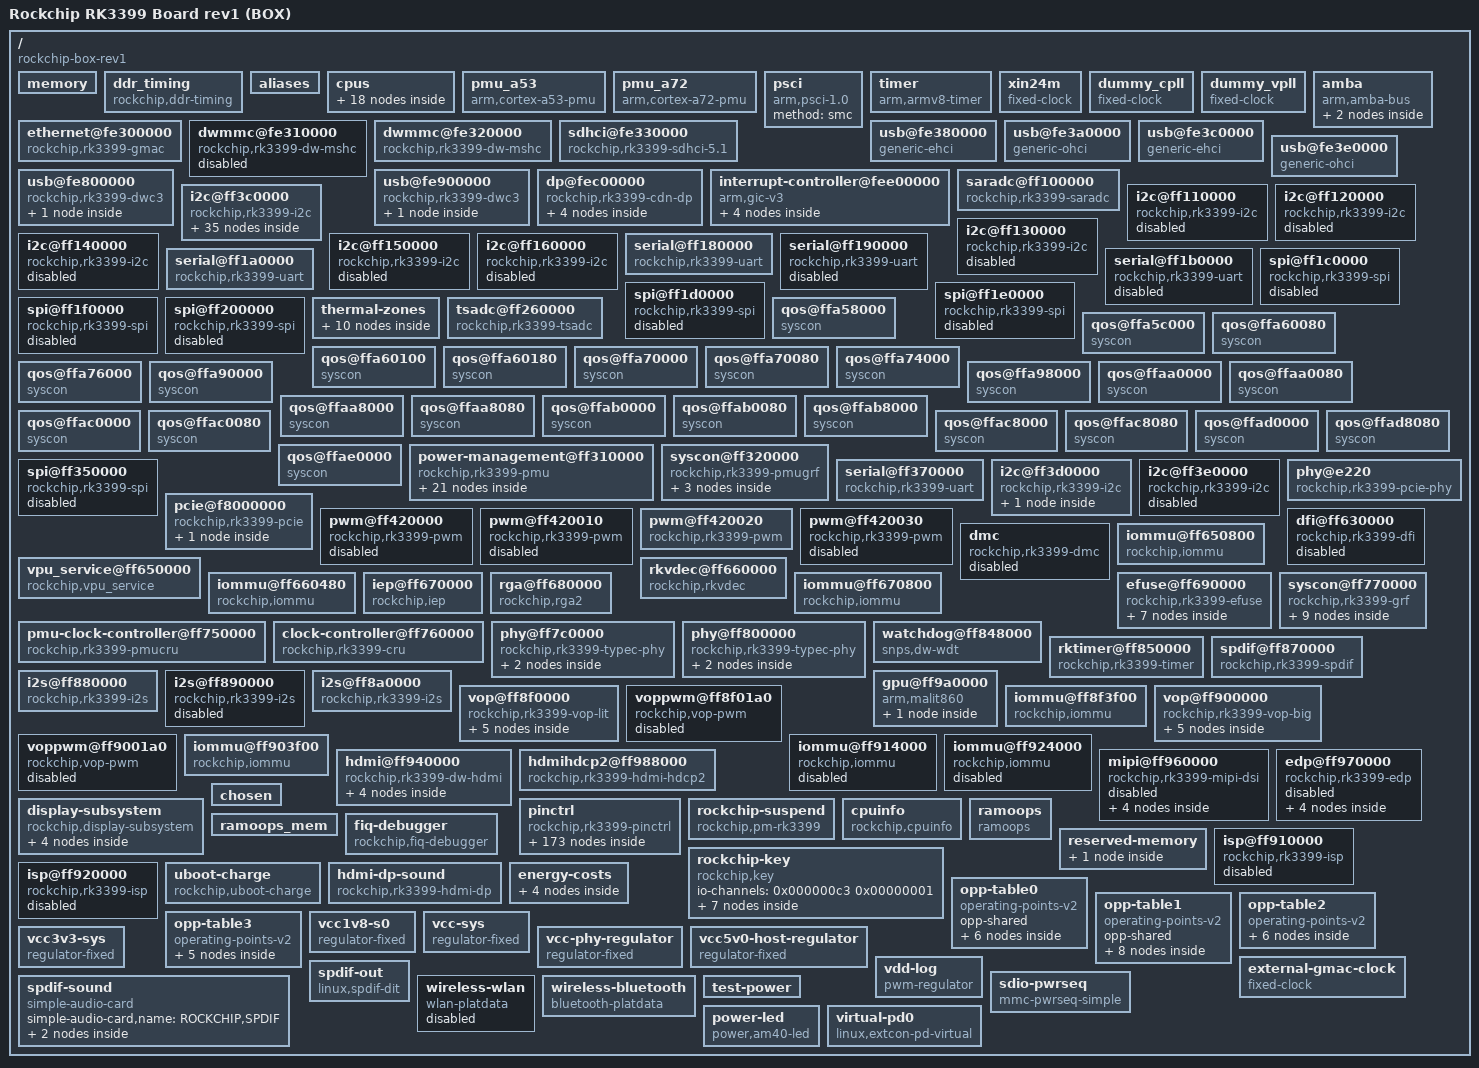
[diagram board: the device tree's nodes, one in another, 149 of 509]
/dts-v1/;
// magic:		0xd00dfeed
// totalsize:		0x12080 (73856)
// off_dt_struct:	0x58
// off_dt_strings:	0xfeb8
// off_mem_rsvmap:	0x28
// version:		17
// last_comp_version:	16
// boot_cpuid_phys:	0x0
// size_dt_strings:	0x136e
// size_dt_struct:	0xfe60

/memreserve/ 0x5600000 0x12000;
/memreserve/ 0x5bf0000 0x1adaf8;
/ {
    compatible = "rockchip-box-rev1", "rockchip,rk3399-box";
    interrupt-parent = <0x00000001>;
    #address-cells = <0x00000002>;
    #size-cells = <0x00000002>;
    model = "Rockchip RK3399 Board rev1 (BOX)";
    memory {
        reg = <0x00000000 0x00200000 0x00000000 0x08200000 0x00000000 0x09400000 0x00000000 0xeec00000>;
        device_type = "memory";
    };
    ddr_timing {
        compatible = "rockchip,ddr-timing";
        ddr3_speed_bin = <0x00000015>;
        pd_idle = <0x00000000>;
        sr_idle = <0x00000000>;
        sr_mc_gate_idle = <0x00000000>;
        srpd_lite_idle = <0x00000000>;
        standby_idle = <0x00000000>;
        dram_dll_dis_freq = <0x0000012c>;
        phy_dll_dis_freq = <0x0000007d>;
        ddr3_odt_dis_freq = <0x0000014d>;
        ddr3_drv = <0x00000028>;
        ddr3_odt = <0x00000078>;
        phy_ddr3_ca_drv = <0x00000028>;
        phy_ddr3_dq_drv = <0x00000028>;
        phy_ddr3_odt = <0x000000f0>;
        lpddr3_odt_dis_freq = <0x0000014d>;
        lpddr3_drv = <0x00000022>;
        lpddr3_odt = <0x000000f0>;
        phy_lpddr3_ca_drv = <0x00000028>;
        phy_lpddr3_dq_drv = <0x00000028>;
        phy_lpddr3_odt = <0x000000f0>;
        lpddr4_odt_dis_freq = <0x0000014d>;
        lpddr4_drv = <0x0000003c>;
        lpddr4_dq_odt = <0x00000028>;
        lpddr4_ca_odt = <0x00000028>;
        phy_lpddr4_ca_drv = <0x00000028>;
        phy_lpddr4_ck_cs_drv = <0x00000050>;
        phy_lpddr4_dq_drv = <0x00000050>;
        phy_lpddr4_odt = <0x0000003c>;
        linux,phandle = <0x0000008b>;
        phandle = <0x0000008b>;
    };
    aliases {
        i2c0 = "/i2c@ff3c0000";
        i2c1 = "/i2c@ff110000";
        i2c2 = "/i2c@ff120000";
        i2c3 = "/i2c@ff130000";
        i2c4 = "/i2c@ff3d0000";
        i2c5 = "/i2c@ff140000";
        i2c6 = "/i2c@ff150000";
        i2c7 = "/i2c@ff160000";
        i2c8 = "/i2c@ff3e0000";
        serial0 = "/serial@ff180000";
        serial1 = "/serial@ff190000";
        serial2 = "/serial@ff1a0000";
        serial3 = "/serial@ff1b0000";
        serial4 = "/serial@ff370000";
    };
    cpus {
        #address-cells = <0x00000002>;
        #size-cells = <0x00000000>;
        cpu-map {
            cluster0 {
                core0 {
                    cpu = <0x00000002>;
                };
                core1 {
                    cpu = <0x00000003>;
                };
                core2 {
                    cpu = <0x00000004>;
                };
                core3 {
                    cpu = <0x00000005>;
                };
            };
            cluster1 {
                core0 {
                    cpu = <0x00000006>;
                };
                core1 {
                    cpu = <0x00000007>;
                };
            };
        };
        cpu@0 {
            device_type = "cpu";
            compatible = "arm,cortex-a53", "arm,armv8";
            reg = <0x00000000 0x00000000>;
            enable-method = "psci";
            #cooling-cells = <0x00000002>;
            dynamic-power-coefficient = <0x00000064>;
            clocks = <0x00000008 0x00000008>;
            cpu-idle-states = <0x00000009 0x0000000a>;
            operating-points-v2 = <0x0000000b>;
            sched-energy-costs = <0x0000000c 0x0000000d>;
            cpu-supply = <0x0000000e>;
            linux,phandle = <0x00000002>;
            phandle = <0x00000002>;
        };
        cpu@1 {
            device_type = "cpu";
            compatible = "arm,cortex-a53", "arm,armv8";
            reg = <0x00000000 0x00000001>;
            enable-method = "psci";
            clocks = <0x00000008 0x00000008>;
            cpu-idle-states = <0x00000009 0x0000000a>;
            operating-points-v2 = <0x0000000b>;
            sched-energy-costs = <0x0000000c 0x0000000d>;
            cpu-supply = <0x0000000e>;
            linux,phandle = <0x00000003>;
            phandle = <0x00000003>;
        };
        cpu@2 {
            device_type = "cpu";
            compatible = "arm,cortex-a53", "arm,armv8";
            reg = <0x00000000 0x00000002>;
            enable-method = "psci";
            clocks = <0x00000008 0x00000008>;
            cpu-idle-states = <0x00000009 0x0000000a>;
            operating-points-v2 = <0x0000000b>;
            sched-energy-costs = <0x0000000c 0x0000000d>;
            cpu-supply = <0x0000000e>;
            linux,phandle = <0x00000004>;
            phandle = <0x00000004>;
        };
        cpu@3 {
            device_type = "cpu";
            compatible = "arm,cortex-a53", "arm,armv8";
            reg = <0x00000000 0x00000003>;
            enable-method = "psci";
            clocks = <0x00000008 0x00000008>;
            cpu-idle-states = <0x00000009 0x0000000a>;
            operating-points-v2 = <0x0000000b>;
            sched-energy-costs = <0x0000000c 0x0000000d>;
            cpu-supply = <0x0000000e>;
            linux,phandle = <0x00000005>;
            phandle = <0x00000005>;
        };
        cpu@100 {
            device_type = "cpu";
            compatible = "arm,cortex-a72", "arm,armv8";
            reg = <0x00000000 0x00000100>;
            enable-method = "psci";
            #cooling-cells = <0x00000002>;
            dynamic-power-coefficient = <0x000001b4>;
            clocks = <0x00000008 0x00000009>;
            cpu-idle-states = <0x00000009 0x0000000a>;
            operating-points-v2 = <0x0000000f>;
            sched-energy-costs = <0x00000010 0x00000011>;
            cpu-supply = <0x00000012>;
            linux,phandle = <0x00000006>;
            phandle = <0x00000006>;
        };
        cpu@101 {
            device_type = "cpu";
            compatible = "arm,cortex-a72", "arm,armv8";
            reg = <0x00000000 0x00000101>;
            enable-method = "psci";
            clocks = <0x00000008 0x00000009>;
            cpu-idle-states = <0x00000009 0x0000000a>;
            operating-points-v2 = <0x0000000f>;
            sched-energy-costs = <0x00000010 0x00000011>;
            cpu-supply = <0x00000012>;
            linux,phandle = <0x00000007>;
            phandle = <0x00000007>;
        };
        idle-states {
            entry-method = "psci";
            cpu-sleep {
                compatible = "arm,idle-state";
                local-timer-stop;
                arm,psci-suspend-param = <0x00010000>;
                entry-latency-us = <0x00000078>;
                exit-latency-us = <0x000000fa>;
                min-residency-us = <0x00000384>;
                linux,phandle = <0x00000009>;
                phandle = <0x00000009>;
            };
            cluster-sleep {
                compatible = "arm,idle-state";
                local-timer-stop;
                arm,psci-suspend-param = <0x01010000>;
                entry-latency-us = <0x00000190>;
                exit-latency-us = <0x000001f4>;
                min-residency-us = <0x000007d0>;
                linux,phandle = <0x0000000a>;
                phandle = <0x0000000a>;
            };
        };
    };
    pmu_a53 {
        compatible = "arm,cortex-a53-pmu";
        interrupts = <0x00000001 0x00000007 0x00000008 0x00000013>;
    };
    pmu_a72 {
        compatible = "arm,cortex-a72-pmu";
        interrupts = <0x00000001 0x00000007 0x00000008 0x00000014>;
    };
    psci {
        compatible = "arm,psci-1.0";
        method = "smc";
    };
    timer {
        compatible = "arm,armv8-timer";
        interrupts = <0x00000001 0x0000000d 0x00000008 0x00000000 0x00000001 0x0000000e 0x00000008 0x00000000 0x00000001 0x0000000b 0x00000008 0x00000000 0x00000001 0x0000000a 0x00000008 0x00000000>;
    };
    xin24m {
        compatible = "fixed-clock";
        clock-frequency = <0x016e3600>;
        clock-output-names = "xin24m";
        #clock-cells = <0x00000000>;
    };
    dummy_cpll {
        compatible = "fixed-clock";
        clock-frequency = <0x00000000>;
        clock-output-names = "dummy_cpll";
        #clock-cells = <0x00000000>;
    };
    dummy_vpll {
        compatible = "fixed-clock";
        clock-frequency = <0x00000000>;
        clock-output-names = "dummy_vpll";
        #clock-cells = <0x00000000>;
    };
    amba {
        compatible = "arm,amba-bus";
        #address-cells = <0x00000002>;
        #size-cells = <0x00000002>;
        ranges;
        dma-controller@ff6d0000 {
            compatible = "arm,pl330", "arm,primecell";
            reg = <0x00000000 0xff6d0000 0x00000000 0x00004000>;
            interrupts = <0x00000000 0x00000005 0x00000004 0x00000000 0x00000000 0x00000006 0x00000004 0x00000000>;
            #dma-cells = <0x00000001>;
            clocks = <0x00000008 0x000000d3>;
            clock-names = "apb_pclk";
            peripherals-req-type-burst;
            linux,phandle = <0x00000094>;
            phandle = <0x00000094>;
        };
        dma-controller@ff6e0000 {
            compatible = "arm,pl330", "arm,primecell";
            reg = <0x00000000 0xff6e0000 0x00000000 0x00004000>;
            interrupts = <0x00000000 0x00000007 0x00000004 0x00000000 0x00000000 0x00000008 0x00000004 0x00000000>;
            #dma-cells = <0x00000001>;
            clocks = <0x00000008 0x000000d4>;
            clock-names = "apb_pclk";
            peripherals-req-type-burst;
        };
    };
    ethernet@fe300000 {
        compatible = "rockchip,rk3399-gmac";
        reg = <0x00000000 0xfe300000 0x00000000 0x00010000>;
        rockchip,grf = <0x00000015>;
        interrupts = <0x00000000 0x0000000c 0x00000004 0x00000000>;
        interrupt-names = "macirq";
        clocks = <0x00000008 0x00000069 0x00000008 0x00000067 0x00000008 0x00000068 0x00000008 0x00000066 0x00000008 0x0000006a 0x00000008 0x000000d5 0x00000008 0x00000166>;
        clock-names = "stmmaceth", "mac_clk_rx", "mac_clk_tx", "clk_mac_ref", "clk_mac_refout", "aclk_mac", "pclk_mac";
        resets = <0x00000008 0x00000089>;
        reset-names = "stmmaceth";
        status = "okay";
        phy-supply = <0x00000016>;
        phy-mode = "rgmii";
        clock_in_out = "input";
        snps,reset-gpio = <0x00000017 0x0000000f 0x00000001>;
        snps,reset-active-low;
        snps,reset-delays-us = <0x00000000 0x000186a0 0x000186a0>;
        assigned-clocks = <0x00000008 0x000000a6>;
        assigned-clock-parents = <0x00000018>;
        pinctrl-names = "default";
        pinctrl-0 = <0x00000019>;
        wolirq-gpio = <0x0000001a 0x00000014 0x00000001>;
        tx_delay = <0x00000028>;
        rx_delay = <0x00000011>;
        lan_name = "RTL8211F";
        wakeup_ms = <0x00003a98>;
    };
    dwmmc@fe310000 {
        compatible = "rockchip,rk3399-dw-mshc", "rockchip,rk3288-dw-mshc";
        reg = <0x00000000 0xfe310000 0x00000000 0x00004000>;
        interrupts = <0x00000000 0x00000040 0x00000004 0x00000000>;
        clock-freq-min-max = <0x00030d40 0x05f5e100>;
        clocks = <0x00000008 0x000001ee 0x00000008 0x0000004d 0x00000008 0x0000009c 0x00000008 0x0000009d>;
        clock-names = "biu", "ciu", "ciu-drive", "ciu-sample";
        fifo-depth = <0x00000100>;
        power-domains = <0x0000001b 0x0000001c>;
        status = "disabled";
        clock-frequency = <0x05f5e100>;
        supports-sdio;
        bus-width = <0x00000004>;
        disable-wp;
        cap-sd-highspeed;
        cap-sdio-irq;
        keep-power-in-suspend;
        mmc-pwrseq = <0x0000001c>;
        non-removable;
        num-slots = <0x00000001>;
        pinctrl-names = "default";
        pinctrl-0 = <0x0000001d 0x0000001e 0x0000001f>;
        sd-uhs-sdr104;
    };
    dwmmc@fe320000 {
        compatible = "rockchip,rk3399-dw-mshc", "rockchip,rk3288-dw-mshc";
        reg = <0x00000000 0xfe320000 0x00000000 0x00004000>;
        interrupts = <0x00000000 0x00000041 0x00000004 0x00000000>;
        clock-freq-min-max = <0x000186a0 0x05f5e100>;
        clocks = <0x00000008 0x000001ce 0x00000008 0x0000004c 0x00000008 0x0000009a 0x00000008 0x0000009b>;
        clock-names = "biu", "ciu", "ciu-drive", "ciu-sample";
        fifo-depth = <0x00000100>;
        power-domains = <0x0000001b 0x0000001b>;
        status = "okay";
        clock-frequency = <0x05f5e100>;
        supports-sd;
        bus-width = <0x00000004>;
        cap-mmc-highspeed;
        cap-sd-highspeed;
        disable-wp;
        num-slots = <0x00000001>;
        vqmmc-supply = <0x00000020>;
        pinctrl-names = "default";
        pinctrl-0 = <0x00000021 0x00000022 0x00000023 0x00000024>;
        card-detect-delay = <0x00000320>;
    };
    sdhci@fe330000 {
        compatible = "rockchip,rk3399-sdhci-5.1", "arasan,sdhci-5.1";
        reg = <0x00000000 0xfe330000 0x00000000 0x00010000>;
        interrupts = <0x00000000 0x0000000b 0x00000004 0x00000000>;
        arasan,soc-ctl-syscon = <0x00000015>;
        assigned-clocks = <0x00000008 0x0000004e>;
        assigned-clock-rates = <0x0bebc200>;
        clocks = <0x00000008 0x0000004e 0x00000008 0x000000f0>;
        clock-names = "clk_xin", "clk_ahb";
        clock-output-names = "emmc_cardclock";
        #clock-cells = <0x00000000>;
        phys = <0x00000025>;
        phy-names = "phy_arasan";
        power-domains = <0x0000001b 0x00000017>;
        status = "okay";
        assigned-clock-parents = <0x00000008 0x00000005>;
        bus-width = <0x00000008>;
        mmc-hs400-1_8v;
        supports-emmc;
        non-removable;
        mmc-hs400-enhanced-strobe;
        linux,phandle = <0x00000092>;
        phandle = <0x00000092>;
    };
    usb@fe380000 {
        compatible = "generic-ehci";
        reg = <0x00000000 0xfe380000 0x00000000 0x00020000>;
        interrupts = <0x00000000 0x0000001a 0x00000004 0x00000000>;
        clocks = <0x00000008 0x000001c8 0x00000008 0x000001c9 0x00000008 0x000000a8>;
        clock-names = "hclk_host0", "hclk_host0_arb", "usbphy0_480m";
        phys = <0x00000026>;
        phy-names = "usb";
        power-domains = <0x0000001b 0x0000000e>;
        status = "okay";
    };
    usb@fe3a0000 {
        compatible = "generic-ohci";
        reg = <0x00000000 0xfe3a0000 0x00000000 0x00020000>;
        interrupts = <0x00000000 0x0000001c 0x00000004 0x00000000>;
        clocks = <0x00000008 0x000001c8 0x00000008 0x000001c9 0x00000008 0x000000a8>;
        clock-names = "hclk_host0", "hclk_host0_arb", "usbphy0_480m";
        phys = <0x00000026>;
        phy-names = "usb";
        power-domains = <0x0000001b 0x0000000e>;
        status = "okay";
    };
    usb@fe3c0000 {
        compatible = "generic-ehci";
        reg = <0x00000000 0xfe3c0000 0x00000000 0x00020000>;
        interrupts = <0x00000000 0x0000001e 0x00000004 0x00000000>;
        clocks = <0x00000008 0x000001ca 0x00000008 0x000001cb 0x00000008 0x000000a9>;
        clock-names = "hclk_host1", "hclk_host1_arb", "usbphy1_480m";
        phys = <0x00000027>;
        phy-names = "usb";
        power-domains = <0x0000001b 0x0000000e>;
        status = "okay";
    };
    usb@fe3e0000 {
        compatible = "generic-ohci";
        reg = <0x00000000 0xfe3e0000 0x00000000 0x00020000>;
        interrupts = <0x00000000 0x00000020 0x00000004 0x00000000>;
        clocks = <0x00000008 0x000001ca 0x00000008 0x000001cb 0x00000008 0x000000a9>;
        clock-names = "hclk_host1", "hclk_host1_arb", "usbphy1_480m";
        phys = <0x00000027>;
        phy-names = "usb";
        power-domains = <0x0000001b 0x0000000e>;
        status = "okay";
    };
    usb@fe800000 {
        compatible = "rockchip,rk3399-dwc3";
        clocks = <0x00000008 0x00000081 0x00000008 0x00000083 0x00000008 0x000000f6 0x00000008 0x000000f9>;
        clock-names = "ref_clk", "suspend_clk", "bus_clk", "grf_clk";
        power-domains = <0x0000001b 0x00000018>;
        resets = <0x00000008 0x00000125>;
        reset-names = "usb3-otg";
        #address-cells = <0x00000002>;
        #size-cells = <0x00000002>;
        ranges;
        status = "okay";
        extcon = <0x00000028>;
        dwc3@fe800000 {
            compatible = "snps,dwc3";
            reg = <0x00000000 0xfe800000 0x00000000 0x00100000>;
            interrupts = <0x00000000 0x00000069 0x00000004 0x00000000>;
            dr_mode = "otg";
            phys = <0x00000029 0x0000002a>;
            phy-names = "usb2-phy", "usb3-phy";
            phy_type = "utmi_wide";
            snps,dis_enblslpm_quirk;
            snps,dis-u2-freeclk-exists-quirk;
            snps,dis_u2_susphy_quirk;
            snps,dis-del-phy-power-chg-quirk;
            snps,tx-ipgap-linecheck-dis-quirk;
            snps,xhci-slow-suspend-quirk;
            snps,usb3-warm-reset-on-resume-quirk;
            status = "okay";
        };
    };
    usb@fe900000 {
        compatible = "rockchip,rk3399-dwc3";
        clocks = <0x00000008 0x00000082 0x00000008 0x00000084 0x00000008 0x000000f7 0x00000008 0x000000f9>;
        clock-names = "ref_clk", "suspend_clk", "bus_clk", "grf_clk";
        power-domains = <0x0000001b 0x00000018>;
        resets = <0x00000008 0x00000126>;
        reset-names = "usb3-otg";
        #address-cells = <0x00000002>;
        #size-cells = <0x00000002>;
        ranges;
        status = "okay";
        dwc3@fe900000 {
            compatible = "snps,dwc3";
            reg = <0x00000000 0xfe900000 0x00000000 0x00100000>;
            interrupts = <0x00000000 0x0000006e 0x00000004 0x00000000>;
            dr_mode = "host";
            phys = <0x0000002b 0x0000002c>;
            phy-names = "usb2-phy", "usb3-phy";
            phy_type = "utmi_wide";
            snps,dis_enblslpm_quirk;
            snps,dis-u2-freeclk-exists-quirk;
            snps,dis_u2_susphy_quirk;
            snps,dis-del-phy-power-chg-quirk;
            snps,tx-ipgap-linecheck-dis-quirk;
            snps,xhci-slow-suspend-quirk;
            snps,usb3-warm-reset-on-resume-quirk;
            status = "okay";
        };
    };
    dp@fec00000 {
        compatible = "rockchip,rk3399-cdn-dp";
        reg = <0x00000000 0xfec00000 0x00000000 0x00100000>;
        interrupts = <0x00000000 0x00000009 0x00000004>;
        clocks = <0x00000008 0x00000072 0x00000008 0x00000175 0x00000008 0x000000a1 0x00000008 0x0000016f>;
        clock-names = "core-clk", "pclk", "spdif", "grf";
        assigned-clocks = <0x00000008 0x00000072>;
        assigned-clock-rates = <0x05f5e100>;
        power-domains = <0x0000001b 0x00000015>;
        phys = <0x0000002d 0x0000002e>;
        resets = <0x00000008 0x00000103 0x00000008 0x00000148 0x00000008 0x0000014a 0x00000008 0x000000fd>;
        reset-names = "spdif", "dptx", "apb", "core";
        rockchip,grf = <0x00000015>;
        #address-cells = <0x00000001>;
        #size-cells = <0x00000000>;
        #sound-dai-cells = <0x00000001>;
        status = "okay";
        extcon = <0x0000002f>;
        dp_vop_sel = <0x00000001>;
        linux,phandle = <0x000000cd>;
        phandle = <0x000000cd>;
        ports {
            #address-cells = <0x00000001>;
            #size-cells = <0x00000000>;
            port {
                #address-cells = <0x00000001>;
                #size-cells = <0x00000000>;
                endpoint@0 {
                    reg = <0x00000000>;
                    remote-endpoint = <0x00000030>;
                    status = "disabled";
                    linux,phandle = <0x000000a4>;
                    phandle = <0x000000a4>;
                };
                endpoint@1 {
                    reg = <0x00000001>;
                    remote-endpoint = <0x00000031>;
                    linux,phandle = <0x0000009e>;
                    phandle = <0x0000009e>;
                };
            };
        };
    };
    interrupt-controller@fee00000 {
        compatible = "arm,gic-v3";
        #interrupt-cells = <0x00000004>;
        #address-cells = <0x00000002>;
        #size-cells = <0x00000002>;
        ranges;
        interrupt-controller;
        reg = <0x00000000 0xfee00000 0x00000000 0x00010000 0x00000000 0xfef00000 0x00000000 0x000c0000 0x00000000 0xfff00000 0x00000000 0x00010000 0x00000000 0xfff10000 0x00000000 0x00010000 0x00000000 0xfff20000 0x00000000 0x00010000>;
        interrupts = <0x00000001 0x00000009 0x00000004 0x00000000>;
        linux,phandle = <0x00000001>;
        phandle = <0x00000001>;
        interrupt-controller@fee20000 {
            compatible = "arm,gic-v3-its";
            msi-controller;
            reg = <0x00000000 0xfee20000 0x00000000 0x00020000>;
            linux,phandle = <0x00000081>;
            phandle = <0x00000081>;
        };
        ppi-partitions {
            interrupt-partition-0 {
                affinity = <0x00000002 0x00000003 0x00000004 0x00000005>;
                linux,phandle = <0x00000013>;
                phandle = <0x00000013>;
            };
            interrupt-partition-1 {
                affinity = <0x00000006 0x00000007>;
                linux,phandle = <0x00000014>;
                phandle = <0x00000014>;
            };
        };
    };
    saradc@ff100000 {
        compatible = "rockchip,rk3399-saradc";
        reg = <0x00000000 0xff100000 0x00000000 0x00000100>;
        interrupts = <0x00000000 0x0000003e 0x00000004 0x00000000>;
        #io-channel-cells = <0x00000001>;
        clocks = <0x00000008 0x00000050 0x00000008 0x00000165>;
        clock-names = "saradc", "apb_pclk";
        resets = <0x00000008 0x000000d4>;
        reset-names = "saradc-apb";
        status = "okay";
        linux,phandle = <0x000000c3>;
        phandle = <0x000000c3>;
    };
    i2c@ff3c0000 {
        compatible = "rockchip,rk3399-i2c";
        reg = <0x00000000 0xff3c0000 0x00000000 0x00001000>;
        clocks = <0x00000032 0x00000009 0x00000032 0x0000001b>;
        clock-names = "i2c", "pclk";
        interrupts = <0x00000000 0x00000039 0x00000004 0x00000000>;
        pinctrl-names = "default";
        pinctrl-0 = <0x00000033>;
        #address-cells = <0x00000001>;
        #size-cells = <0x00000000>;
        status = "okay";
        i2c-scl-rising-time-ns = <0x000000a8>;
        i2c-scl-falling-time-ns = <0x00000004>;
        clock-frequency = <0x00061a80>;
        syr827@40 {
            compatible = "silergy,syr827";
            reg = <0x00000040>;
            regulator-compatible = "fan53555-reg";
            pinctrl-0 = <0x00000034>;
            vsel-gpios = <0x0000001a 0x00000011 0x00000000>;
            regulator-name = "vdd_cpu_b";
            regulator-min-microvolt = <0x000adf34>;
            regulator-max-microvolt = <0x0016e360>;
            regulator-ramp-delay = <0x000003e8>;
            fcs,suspend-voltage-selector = <0x00000001>;
            regulator-always-on;
            regulator-boot-on;
            vin-supply = <0x00000035>;
            linux,phandle = <0x00000012>;
            phandle = <0x00000012>;
            regulator-state-mem {
                regulator-off-in-suspend;
            };
        };
        syr828@41 {
            compatible = "silergy,syr828";
            reg = <0x00000041>;
            regulator-compatible = "fan53555-reg";
            pinctrl-0 = <0x00000036>;
            vsel-gpios = <0x0000001a 0x0000000e 0x00000000>;
            regulator-name = "vdd_gpu";
            regulator-min-microvolt = <0x000adf34>;
            regulator-max-microvolt = <0x0016e360>;
            regulator-ramp-delay = <0x000003e8>;
            fcs,suspend-voltage-selector = <0x00000001>;
            regulator-always-on;
            regulator-boot-on;
            vin-supply = <0x00000035>;
            regulator-initial-mode = <0x00000001>;
            linux,phandle = <0x00000099>;
            phandle = <0x00000099>;
            regulator-state-mem {
                regulator-off-in-suspend;
            };
        };
        pmic@1b {
            compatible = "rockchip,rk808";
            reg = <0x0000001b>;
            interrupt-parent = <0x0000001a>;
            interrupts = <0x00000015 0x00000008>;
            pinctrl-names = "default";
            pinctrl-0 = <0x00000037>;
            rockchip,system-power-controller;
            wakeup-source;
            #clock-cells = <0x00000001>;
            clock-output-names = "xin32k", "rk808-clkout2";
            vcc1-supply = <0x00000035>;
            vcc2-supply = <0x00000035>;
            vcc3-supply = <0x00000035>;
            vcc4-supply = <0x00000035>;
            vcc6-supply = <0x00000035>;
            vcc7-supply = <0x00000035>;
            vcc8-supply = <0x00000038>;
            vcc9-supply = <0x00000035>;
            vcc10-supply = <0x00000035>;
            vcc11-supply = <0x00000035>;
            vcc12-supply = <0x00000038>;
            vddio-supply = <0x00000039>;
            linux,phandle = <0x000000d3>;
            phandle = <0x000000d3>;
            rtc {
                status = "disabled";
            };
            regulators {
                DCDC_REG1 {
                    regulator-name = "vdd_center";
                    regulator-min-microvolt = <0x000b71b0>;
                    regulator-max-microvolt = <0x00149970>;
                    regulator-ramp-delay = <0x00001771>;
                    regulator-always-on;
                    regulator-boot-on;
                    regulator-state-mem {
                        regulator-off-in-suspend;
                    };
                };
                DCDC_REG2 {
                    regulator-name = "vdd_cpu_l";
                    regulator-min-microvolt = <0x000b71b0>;
                    regulator-max-microvolt = <0x00149970>;
                    regulator-ramp-delay = <0x00001771>;
                    regulator-always-on;
                    regulator-boot-on;
                    linux,phandle = <0x0000000e>;
                    phandle = <0x0000000e>;
                    regulator-state-mem {
                        regulator-off-in-suspend;
                    };
                };
                DCDC_REG3 {
                    regulator-name = "vcc_ddr";
                    regulator-always-on;
                    regulator-boot-on;
                    regulator-state-mem {
                        regulator-on-in-suspend;
                    };
                };
                DCDC_REG4 {
                    regulator-name = "vcc_1v8";
                    regulator-min-microvolt = <0x001b7740>;
                    regulator-max-microvolt = <0x001b7740>;
                    regulator-always-on;
                    regulator-boot-on;
                    linux,phandle = <0x00000039>;
                    phandle = <0x00000039>;
                    regulator-state-mem {
                        regulator-on-in-suspend;
                        regulator-suspend-microvolt = <0x001b7740>;
                    };
                };
                LDO_REG1 {
                    regulator-name = "vcc1v8_dvp";
                    regulator-min-microvolt = <0x001b7740>;
                    regulator-max-microvolt = <0x001b7740>;
                    regulator-always-on;
                    regulator-boot-on;
                    regulator-state-mem {
                        regulator-on-in-suspend;
                        regulator-suspend-microvolt = <0x001b7740>;
                    };
                };
                LDO_REG2 {
                    regulator-name = "vcca1v8_hdmi";
                    regulator-min-microvolt = <0x001b7740>;
                    regulator-max-microvolt = <0x001b7740>;
                    regulator-always-on;
                    regulator-boot-on;
                    regulator-state-mem {
                        regulator-off-in-suspend;
                    };
                };
                LDO_REG3 {
                    regulator-name = "vcca_1v8";
                    regulator-min-microvolt = <0x001b7740>;
                    regulator-max-microvolt = <0x001b7740>;
                    regulator-always-on;
                    regulator-boot-on;
                    regulator-state-mem {
                        regulator-on-in-suspend;
                        regulator-suspend-microvolt = <0x001b7740>;
                    };
                };
                LDO_REG4 {
                    regulator-name = "vcc_sd";
                    regulator-min-microvolt = <0x001b7740>;
                    regulator-max-microvolt = <0x002dc6c0>;
                    regulator-always-on;
                    regulator-boot-on;
                    linux,phandle = <0x00000020>;
                    phandle = <0x00000020>;
                    regulator-state-mem {
                        regulator-off-in-suspend;
                    };
                };
                LDO_REG5 {
                    regulator-name = "vcc3v0_sd";
                    regulator-min-microvolt = <0x002dc6c0>;
                    regulator-max-microvolt = <0x002dc6c0>;
                    regulator-always-on;
                    regulator-boot-on;
                    regulator-state-mem {
                        regulator-off-in-suspend;
                    };
                };
                LDO_REG6 {
                    regulator-name = "vcc_1v5";
                    regulator-min-microvolt = <0x0016e360>;
                    regulator-max-microvolt = <0x0016e360>;
                    regulator-always-on;
                    regulator-boot-on;
                    regulator-state-mem {
                        regulator-off-in-suspend;
                    };
                };
                LDO_REG7 {
                    regulator-name = "vcca0v9_hdmi";
                    regulator-min-microvolt = <0x000dbba0>;
                    regulator-max-microvolt = <0x000dbba0>;
                    regulator-always-on;
                    regulator-boot-on;
                    regulator-state-mem {
                        regulator-off-in-suspend;
                    };
                };
                LDO_REG8 {
                    regulator-name = "vcc_3v0";
                    regulator-min-microvolt = <0x002dc6c0>;
                    regulator-max-microvolt = <0x002dc6c0>;
                    regulator-always-on;
                    regulator-boot-on;
                    linux,phandle = <0x00000091>;
                    phandle = <0x00000091>;
                    regulator-state-mem {
                        regulator-off-in-suspend;
                    };
                };
                SWITCH_REG1 {
                    regulator-name = "vcc3v3_s3";
                    regulator-always-on;
                    regulator-boot-on;
                    regulator-state-mem {
                        regulator-on-in-suspend;
                    };
                };
                SWITCH_REG2 {
                    regulator-name = "vcc3v3_s0";
                    regulator-always-on;
                    regulator-boot-on;
                    regulator-state-mem {
                        regulator-on-in-suspend;
                    };
                };
            };
        };
    };
    i2c@ff110000 {
        compatible = "rockchip,rk3399-i2c";
        reg = <0x00000000 0xff110000 0x00000000 0x00001000>;
        clocks = <0x00000008 0x00000041 0x00000008 0x00000155>;
        clock-names = "i2c", "pclk";
        interrupts = <0x00000000 0x0000003b 0x00000004 0x00000000>;
        pinctrl-names = "default";
        pinctrl-0 = <0x0000003a>;
        #address-cells = <0x00000001>;
        #size-cells = <0x00000000>;
        status = "disabled";
    };
    i2c@ff120000 {
        compatible = "rockchip,rk3399-i2c";
        reg = <0x00000000 0xff120000 0x00000000 0x00001000>;
        clocks = <0x00000008 0x00000042 0x00000008 0x00000156>;
        clock-names = "i2c", "pclk";
        interrupts = <0x00000000 0x00000023 0x00000004 0x00000000>;
        pinctrl-names = "default";
        pinctrl-0 = <0x0000003b>;
        #address-cells = <0x00000001>;
        #size-cells = <0x00000000>;
        status = "disabled";
    };
    i2c@ff130000 {
        compatible = "rockchip,rk3399-i2c";
        reg = <0x00000000 0xff130000 0x00000000 0x00001000>;
        clocks = <0x00000008 0x00000043 0x00000008 0x00000157>;
        clock-names = "i2c", "pclk";
        interrupts = <0x00000000 0x00000022 0x00000004 0x00000000>;
        pinctrl-names = "default";
        pinctrl-0 = <0x0000003c>;
        #address-cells = <0x00000001>;
        #size-cells = <0x00000000>;
        status = "disabled";
    };
    i2c@ff140000 {
        compatible = "rockchip,rk3399-i2c";
        reg = <0x00000000 0xff140000 0x00000000 0x00001000>;
        clocks = <0x00000008 0x00000044 0x00000008 0x00000158>;
        clock-names = "i2c", "pclk";
        interrupts = <0x00000000 0x00000026 0x00000004 0x00000000>;
        pinctrl-names = "default";
        pinctrl-0 = <0x0000003d>;
        #address-cells = <0x00000001>;
        #size-cells = <0x00000000>;
        status = "disabled";
    };
    i2c@ff150000 {
        compatible = "rockchip,rk3399-i2c";
        reg = <0x00000000 0xff150000 0x00000000 0x00001000>;
        clocks = <0x00000008 0x00000045 0x00000008 0x00000159>;
        clock-names = "i2c", "pclk";
        interrupts = <0x00000000 0x00000025 0x00000004 0x00000000>;
        pinctrl-names = "default";
        pinctrl-0 = <0x0000003e>;
        #address-cells = <0x00000001>;
        #size-cells = <0x00000000>;
        status = "disabled";
    };
    i2c@ff160000 {
        compatible = "rockchip,rk3399-i2c";
        reg = <0x00000000 0xff160000 0x00000000 0x00001000>;
        clocks = <0x00000008 0x00000046 0x00000008 0x0000015a>;
        clock-names = "i2c", "pclk";
        interrupts = <0x00000000 0x00000024 0x00000004 0x00000000>;
        pinctrl-names = "default";
        pinctrl-0 = <0x0000003f>;
        #address-cells = <0x00000001>;
        #size-cells = <0x00000000>;
        status = "disabled";
    };
    serial@ff180000 {
        compatible = "rockchip,rk3399-uart", "snps,dw-apb-uart";
        reg = <0x00000000 0xff180000 0x00000000 0x00000100>;
        clocks = <0x00000008 0x00000051 0x00000008 0x00000160>;
        clock-names = "baudclk", "apb_pclk";
        interrupts = <0x00000000 0x00000063 0x00000004 0x00000000>;
        reg-shift = <0x00000002>;
        reg-io-width = <0x00000004>;
        pinctrl-names = "default";
        pinctrl-0 = <0x00000040 0x00000041>;
        status = "okay";
        assigned-clocks = <0x00000008 0x000000ac>;
        assigned-clock-parents = <0x00000008 0x00000005>;
    };
    serial@ff190000 {
        compatible = "rockchip,rk3399-uart", "snps,dw-apb-uart";
        reg = <0x00000000 0xff190000 0x00000000 0x00000100>;
        clocks = <0x00000008 0x00000052 0x00000008 0x00000161>;
        clock-names = "baudclk", "apb_pclk";
        interrupts = <0x00000000 0x00000062 0x00000004 0x00000000>;
        reg-shift = <0x00000002>;
        reg-io-width = <0x00000004>;
        pinctrl-names = "default";
        pinctrl-0 = <0x00000042>;
        status = "disabled";
        assigned-clocks = <0x00000008 0x000000ad>;
        assigned-clock-parents = <0x00000008 0x00000005>;
    };
    serial@ff1a0000 {
        compatible = "rockchip,rk3399-uart", "snps,dw-apb-uart";
        reg = <0x00000000 0xff1a0000 0x00000000 0x00000100>;
        clocks = <0x00000008 0x00000053 0x00000008 0x00000162>;
        clock-names = "baudclk", "apb_pclk";
        interrupts = <0x00000000 0x00000064 0x00000004 0x00000000>;
        reg-shift = <0x00000002>;
        reg-io-width = <0x00000004>;
        pinctrl-names = "default";
        pinctrl-0 = <0x00000043>;
        status = "okay";
        assigned-clocks = <0x00000008 0x000000ad>;
        assigned-clock-parents = <0x00000008 0x00000005>;
    };
    serial@ff1b0000 {
        compatible = "rockchip,rk3399-uart", "snps,dw-apb-uart";
        reg = <0x00000000 0xff1b0000 0x00000000 0x00000100>;
        clocks = <0x00000008 0x00000054 0x00000008 0x00000163>;
        clock-names = "baudclk", "apb_pclk";
        interrupts = <0x00000000 0x00000065 0x00000004 0x00000000>;
        reg-shift = <0x00000002>;
        reg-io-width = <0x00000004>;
        pinctrl-names = "default";
        pinctrl-0 = <0x00000044 0x00000045 0x00000046>;
        status = "disabled";
        assigned-clocks = <0x00000008 0x000000ad>;
        assigned-clock-parents = <0x00000008 0x00000005>;
    };
    spi@ff1c0000 {
        compatible = "rockchip,rk3399-spi", "rockchip,rk3066-spi";
        reg = <0x00000000 0xff1c0000 0x00000000 0x00001000>;
        clocks = <0x00000008 0x00000047 0x00000008 0x0000015b>;
        clock-names = "spiclk", "apb_pclk";
        interrupts = <0x00000000 0x00000044 0x00000004 0x00000000>;
        pinctrl-names = "default";
        pinctrl-0 = <0x00000047 0x00000048 0x00000049 0x0000004a>;
        #address-cells = <0x00000001>;
        #size-cells = <0x00000000>;
        status = "disabled";
    };
    spi@ff1d0000 {
        compatible = "rockchip,rk3399-spi", "rockchip,rk3066-spi";
        reg = <0x00000000 0xff1d0000 0x00000000 0x00001000>;
        clocks = <0x00000008 0x00000048 0x00000008 0x0000015c>;
        clock-names = "spiclk", "apb_pclk";
        interrupts = <0x00000000 0x00000035 0x00000004 0x00000000>;
        pinctrl-names = "default";
        pinctrl-0 = <0x0000004b 0x0000004c 0x0000004d 0x0000004e>;
        #address-cells = <0x00000001>;
        #size-cells = <0x00000000>;
        status = "disabled";
    };
    spi@ff1e0000 {
        compatible = "rockchip,rk3399-spi", "rockchip,rk3066-spi";
        reg = <0x00000000 0xff1e0000 0x00000000 0x00001000>;
        clocks = <0x00000008 0x00000049 0x00000008 0x0000015d>;
        clock-names = "spiclk", "apb_pclk";
        interrupts = <0x00000000 0x00000034 0x00000004 0x00000000>;
        pinctrl-names = "default";
        pinctrl-0 = <0x0000004f 0x00000050 0x00000051 0x00000052>;
        #address-cells = <0x00000001>;
        #size-cells = <0x00000000>;
        status = "disabled";
    };
    spi@ff1f0000 {
        compatible = "rockchip,rk3399-spi", "rockchip,rk3066-spi";
        reg = <0x00000000 0xff1f0000 0x00000000 0x00001000>;
        clocks = <0x00000008 0x0000004a 0x00000008 0x0000015e>;
        clock-names = "spiclk", "apb_pclk";
        interrupts = <0x00000000 0x00000043 0x00000004 0x00000000>;
        pinctrl-names = "default";
        pinctrl-0 = <0x00000053 0x00000054 0x00000055 0x00000056>;
        #address-cells = <0x00000001>;
        #size-cells = <0x00000000>;
        status = "disabled";
    };
    spi@ff200000 {
        compatible = "rockchip,rk3399-spi", "rockchip,rk3066-spi";
        reg = <0x00000000 0xff200000 0x00000000 0x00001000>;
        clocks = <0x00000008 0x0000004b 0x00000008 0x0000015f>;
        clock-names = "spiclk", "apb_pclk";
        interrupts = <0x00000000 0x00000084 0x00000004 0x00000000>;
        pinctrl-names = "default";
        pinctrl-0 = <0x00000057 0x00000058 0x00000059 0x0000005a>;
        #address-cells = <0x00000001>;
        #size-cells = <0x00000000>;
        status = "disabled";
    };
    thermal-zones {
        soc-thermal {
            polling-delay-passive = <0x00000014>;
            polling-delay = <0x000003e8>;
            sustainable-power = <0x000003e8>;
            thermal-sensors = <0x0000005b 0x00000000>;
            trips {
                trip-point@0 {
                    temperature = <0x00014c08>;
                    hysteresis = <0x000007d0>;
                    type = "passive";
                };
                trip-point@1 {
                    temperature = <0x000186a0>;
                    hysteresis = <0x000007d0>;
                    type = "passive";
                    linux,phandle = <0x0000005c>;
                    phandle = <0x0000005c>;
                };
                soc-crit {
                    temperature = <0x00019a28>;
                    hysteresis = <0x000007d0>;
                    type = "critical";
                };
            };
            cooling-maps {
                map0 {
                    trip = <0x0000005c>;
                    cooling-device = <0x00000002 0xffffffff 0xffffffff>;
                    contribution = <0x00001000>;
                };
                map1 {
                    trip = <0x0000005c>;
                    cooling-device = <0x00000006 0xffffffff 0xffffffff>;
                    contribution = <0x00000400>;
                };
                map2 {
                    trip = <0x0000005c>;
                    cooling-device = <0x0000005d 0xffffffff 0xffffffff>;
                    contribution = <0x00001000>;
                };
            };
        };
        gpu-thermal {
            polling-delay-passive = <0x00000064>;
            polling-delay = <0x000003e8>;
            thermal-sensors = <0x0000005b 0x00000001>;
        };
    };
    tsadc@ff260000 {
        compatible = "rockchip,rk3399-tsadc";
        reg = <0x00000000 0xff260000 0x00000000 0x00000100>;
        interrupts = <0x00000000 0x00000061 0x00000004 0x00000000>;
        rockchip,grf = <0x00000015>;
        clocks = <0x00000008 0x0000004f 0x00000008 0x00000164>;
        clock-names = "tsadc", "apb_pclk";
        assigned-clocks = <0x00000008 0x0000004f>;
        assigned-clock-rates = <0x000b71b0>;
        resets = <0x00000008 0x000000e8>;
        reset-names = "tsadc-apb";
        pinctrl-names = "init", "default", "sleep";
        pinctrl-0 = <0x0000005e>;
        pinctrl-1 = <0x0000005f>;
        pinctrl-2 = <0x0000005e>;
        #thermal-sensor-cells = <0x00000001>;
        rockchip,hw-tshut-temp = <0x0001adb0>;
        status = "okay";
        rockchip,hw-tshut-mode = <0x00000001>;
        rockchip,hw-tshut-polarity = <0x00000001>;
        linux,phandle = <0x0000005b>;
        phandle = <0x0000005b>;
    };
    qos@ffa58000 {
        compatible = "syscon";
        reg = <0x00000000 0xffa58000 0x00000000 0x00000020>;
        linux,phandle = <0x00000067>;
        phandle = <0x00000067>;
    };
    qos@ffa5c000 {
        compatible = "syscon";
        reg = <0x00000000 0xffa5c000 0x00000000 0x00000020>;
    };
    qos@ffa60080 {
        compatible = "syscon";
        reg = <0x00000000 0xffa60080 0x00000000 0x00000020>;
        linux,phandle = <0x00000069>;
        phandle = <0x00000069>;
    };
    qos@ffa60100 {
        compatible = "syscon";
        reg = <0x00000000 0xffa60100 0x00000000 0x00000020>;
        linux,phandle = <0x0000006a>;
        phandle = <0x0000006a>;
    };
    qos@ffa60180 {
        compatible = "syscon";
        reg = <0x00000000 0xffa60180 0x00000000 0x00000020>;
        linux,phandle = <0x0000006b>;
        phandle = <0x0000006b>;
    };
    qos@ffa70000 {
        compatible = "syscon";
        reg = <0x00000000 0xffa70000 0x00000000 0x00000020>;
        linux,phandle = <0x0000006e>;
        phandle = <0x0000006e>;
    };
    qos@ffa70080 {
        compatible = "syscon";
        reg = <0x00000000 0xffa70080 0x00000000 0x00000020>;
        linux,phandle = <0x0000006f>;
        phandle = <0x0000006f>;
    };
    qos@ffa74000 {
        compatible = "syscon";
        reg = <0x00000000 0xffa74000 0x00000000 0x00000020>;
        linux,phandle = <0x0000006c>;
        phandle = <0x0000006c>;
    };
    qos@ffa76000 {
        compatible = "syscon";
        reg = <0x00000000 0xffa76000 0x00000000 0x00000020>;
        linux,phandle = <0x0000006d>;
        phandle = <0x0000006d>;
    };
    qos@ffa90000 {
        compatible = "syscon";
        reg = <0x00000000 0xffa90000 0x00000000 0x00000020>;
        linux,phandle = <0x00000070>;
        phandle = <0x00000070>;
    };
    qos@ffa98000 {
        compatible = "syscon";
        reg = <0x00000000 0xffa98000 0x00000000 0x00000020>;
        linux,phandle = <0x00000060>;
        phandle = <0x00000060>;
    };
    qos@ffaa0000 {
        compatible = "syscon";
        reg = <0x00000000 0xffaa0000 0x00000000 0x00000020>;
        linux,phandle = <0x00000071>;
        phandle = <0x00000071>;
    };
    qos@ffaa0080 {
        compatible = "syscon";
        reg = <0x00000000 0xffaa0080 0x00000000 0x00000020>;
        linux,phandle = <0x00000072>;
        phandle = <0x00000072>;
    };
    qos@ffaa8000 {
        compatible = "syscon";
        reg = <0x00000000 0xffaa8000 0x00000000 0x00000020>;
        linux,phandle = <0x00000073>;
        phandle = <0x00000073>;
    };
    qos@ffaa8080 {
        compatible = "syscon";
        reg = <0x00000000 0xffaa8080 0x00000000 0x00000020>;
        linux,phandle = <0x00000074>;
        phandle = <0x00000074>;
    };
    qos@ffab0000 {
        compatible = "syscon";
        reg = <0x00000000 0xffab0000 0x00000000 0x00000020>;
        linux,phandle = <0x00000061>;
        phandle = <0x00000061>;
    };
    qos@ffab0080 {
        compatible = "syscon";
        reg = <0x00000000 0xffab0080 0x00000000 0x00000020>;
        linux,phandle = <0x00000062>;
        phandle = <0x00000062>;
    };
    qos@ffab8000 {
        compatible = "syscon";
        reg = <0x00000000 0xffab8000 0x00000000 0x00000020>;
        linux,phandle = <0x00000063>;
        phandle = <0x00000063>;
    };
    qos@ffac0000 {
        compatible = "syscon";
        reg = <0x00000000 0xffac0000 0x00000000 0x00000020>;
        linux,phandle = <0x00000064>;
        phandle = <0x00000064>;
    };
    qos@ffac0080 {
        compatible = "syscon";
        reg = <0x00000000 0xffac0080 0x00000000 0x00000020>;
        linux,phandle = <0x00000065>;
        phandle = <0x00000065>;
    };
    qos@ffac8000 {
        compatible = "syscon";
        reg = <0x00000000 0xffac8000 0x00000000 0x00000020>;
        linux,phandle = <0x00000075>;
        phandle = <0x00000075>;
    };
    qos@ffac8080 {
        compatible = "syscon";
        reg = <0x00000000 0xffac8080 0x00000000 0x00000020>;
        linux,phandle = <0x00000076>;
        phandle = <0x00000076>;
    };
    qos@ffad0000 {
        compatible = "syscon";
        reg = <0x00000000 0xffad0000 0x00000000 0x00000020>;
        linux,phandle = <0x00000077>;
        phandle = <0x00000077>;
    };
    qos@ffad8080 {
        compatible = "syscon";
        reg = <0x00000000 0xffad8080 0x00000000 0x00000020>;
        linux,phandle = <0x00000068>;
        phandle = <0x00000068>;
    };
    qos@ffae0000 {
        compatible = "syscon";
        reg = <0x00000000 0xffae0000 0x00000000 0x00000020>;
        linux,phandle = <0x00000066>;
        phandle = <0x00000066>;
    };
    power-management@ff310000 {
        compatible = "rockchip,rk3399-pmu", "syscon", "simple-mfd";
        reg = <0x00000000 0xff310000 0x00000000 0x00001000>;
        power-controller {
            compatible = "rockchip,rk3399-power-controller";
            #power-domain-cells = <0x00000001>;
            #address-cells = <0x00000001>;
            #size-cells = <0x00000000>;
            linux,phandle = <0x0000001b>;
            phandle = <0x0000001b>;
            pd_iep@34 {
                reg = <0x00000022>;
                clocks = <0x00000008 0x000000e1 0x00000008 0x000001dd>;
                pm_qos = <0x00000060>;
            };
            pd_rga@33 {
                reg = <0x00000021>;
                clocks = <0x00000008 0x000000dc 0x00000008 0x000001e5>;
                pm_qos = <0x00000061 0x00000062>;
            };
            pd_vcodec@31 {
                reg = <0x0000001f>;
                clocks = <0x00000008 0x000000eb 0x00000008 0x000001ea>;
                pm_qos = <0x00000063>;
            };
            pd_vdu@32 {
                reg = <0x00000020>;
                clocks = <0x00000008 0x000000ed 0x00000008 0x000001ec>;
                pm_qos = <0x00000064 0x00000065>;
            };
            pd_gpu@35 {
                reg = <0x00000023>;
                clocks = <0x00000008 0x000000d0>;
                pm_qos = <0x00000066>;
            };
            pd_edp@25 {
                reg = <0x00000019>;
                clocks = <0x00000008 0x0000016c>;
            };
            pd_emmc@23 {
                reg = <0x00000017>;
                clocks = <0x00000008 0x000000f0>;
                pm_qos = <0x00000067>;
            };
            pd_perihp@14 {
                reg = <0x0000000e>;
                #address-cells = <0x00000001>;
                #size-cells = <0x00000000>;
                clocks = <0x00000008 0x000000c0>;
                pm_qos = <0x00000068 0x00000069 0x0000006a 0x0000006b>;
                pd_sd@27 {
                    reg = <0x0000001b>;
                    clocks = <0x00000008 0x000001ce 0x00000008 0x0000004c>;
                    pm_qos = <0x0000006c>;
                };
            };
            pd_sdioaudio@28 {
                reg = <0x0000001c>;
                clocks = <0x00000008 0x000001ee>;
                pm_qos = <0x0000006d>;
            };
            pd_usb3@24 {
                reg = <0x00000018>;
                clocks = <0x00000008 0x000000f4>;
                pm_qos = <0x0000006e 0x0000006f>;
            };
            pd_vio@15 {
                reg = <0x0000000f>;
                #address-cells = <0x00000001>;
                #size-cells = <0x00000000>;
                pd_hdcp@21 {
                    reg = <0x00000015>;
                    clocks = <0x00000008 0x000000de 0x00000008 0x000001e7 0x00000008 0x00000172>;
                    pm_qos = <0x00000070>;
                };
                pd_isp0@19 {
                    reg = <0x00000013>;
                    clocks = <0x00000008 0x000000e5 0x00000008 0x000001df>;
                    pm_qos = <0x00000071 0x00000072>;
                };
                pd_isp1@20 {
                    reg = <0x00000014>;
                    clocks = <0x00000008 0x000000e6 0x00000008 0x000001e0>;
                    pm_qos = <0x00000073 0x00000074>;
                };
                pd_tcpc0@RK3399_PD_TCPC0 {
                    reg = <0x00000008>;
                    clocks = <0x00000008 0x0000007e 0x00000008 0x0000007d>;
                };
                pd_tcpc1@RK3399_PD_TCPC1 {
                    reg = <0x00000009>;
                    clocks = <0x00000008 0x00000080 0x00000008 0x0000007f>;
                };
                pd_vo@16 {
                    reg = <0x00000010>;
                    #address-cells = <0x00000001>;
                    #size-cells = <0x00000000>;
                    pd_vopb@17 {
                        reg = <0x00000011>;
                        clocks = <0x00000008 0x000000d9 0x00000008 0x000001d9>;
                        pm_qos = <0x00000075 0x00000076>;
                    };
                    pd_vopl@18 {
                        reg = <0x00000012>;
                        clocks = <0x00000008 0x000000db 0x00000008 0x000001db>;
                        pm_qos = <0x00000077>;
                    };
                };
            };
        };
    };
    syscon@ff320000 {
        compatible = "rockchip,rk3399-pmugrf", "syscon", "simple-mfd";
        reg = <0x00000000 0xff320000 0x00000000 0x00001000>;
        #address-cells = <0x00000001>;
        #size-cells = <0x00000001>;
        linux,phandle = <0x00000089>;
        phandle = <0x00000089>;
        io-domains {
            compatible = "rockchip,rk3399-pmu-io-voltage-domain";
            status = "okay";
            pmu1830-supply = <0x00000039>;
        };
        reboot-mode {
            compatible = "syscon-reboot-mode";
            offset = <0x00000300>;
            mode-bootloader = <0x5242c301>;
            mode-charge = <0x5242c30b>;
            mode-fastboot = <0x5242c309>;
            mode-loader = <0x5242c301>;
            mode-normal = <0x5242c300>;
            mode-recovery = <0x5242c303>;
            mode-ums = <0x5242c30c>;
        };
        pmu-pvtm {
            compatible = "rockchip,rk3399-pmu-pvtm";
            clocks = <0x00000032 0x00000007>;
            clock-names = "pmu";
            status = "okay";
        };
    };
    spi@ff350000 {
        compatible = "rockchip,rk3399-spi", "rockchip,rk3066-spi";
        reg = <0x00000000 0xff350000 0x00000000 0x00001000>;
        clocks = <0x00000032 0x00000003 0x00000032 0x0000001f>;
        clock-names = "spiclk", "apb_pclk";
        interrupts = <0x00000000 0x0000003c 0x00000004 0x00000000>;
        pinctrl-names = "default";
        pinctrl-0 = <0x00000078 0x00000079 0x0000007a 0x0000007b>;
        #address-cells = <0x00000001>;
        #size-cells = <0x00000000>;
        status = "disabled";
    };
    serial@ff370000 {
        compatible = "rockchip,rk3399-uart", "snps,dw-apb-uart";
        reg = <0x00000000 0xff370000 0x00000000 0x00000100>;
        clocks = <0x00000032 0x00000006 0x00000032 0x00000022>;
        clock-names = "baudclk", "apb_pclk";
        interrupts = <0x00000000 0x00000066 0x00000004 0x00000000>;
        reg-shift = <0x00000002>;
        reg-io-width = <0x00000004>;
        pinctrl-names = "default";
        pinctrl-0 = <0x0000007c>;
        status = "okay";
        assigned-clocks = <0x00000008 0x000000ad>;
        assigned-clock-parents = <0x00000008 0x00000005>;
    };
    i2c@ff3d0000 {
        compatible = "rockchip,rk3399-i2c";
        reg = <0x00000000 0xff3d0000 0x00000000 0x00001000>;
        clocks = <0x00000032 0x0000000a 0x00000032 0x0000001c>;
        clock-names = "i2c", "pclk";
        interrupts = <0x00000000 0x00000038 0x00000004 0x00000000>;
        pinctrl-names = "default";
        pinctrl-0 = <0x0000007d>;
        #address-cells = <0x00000001>;
        #size-cells = <0x00000000>;
        status = "okay";
        pt7c4563@51 {
            compatible = "Diodes,PT7C4563";
            reg = <0x00000051>;
            clock-frequency = <0x00008000>;
            clock-output-names = "xin32k";
            irq-status = "okay";
            interrupt-parent = <0x0000007e>;
            interrupts = <0x00000006 0x00000008>;
            pinctrl-names = "default";
            pinctrl-0 = <0x0000007f>;
            status = "okay";
        };
    };
    i2c@ff3e0000 {
        compatible = "rockchip,rk3399-i2c";
        reg = <0x00000000 0xff3e0000 0x00000000 0x00001000>;
        clocks = <0x00000032 0x0000000b 0x00000032 0x0000001d>;
        clock-names = "i2c", "pclk";
        interrupts = <0x00000000 0x0000003a 0x00000004 0x00000000>;
        pinctrl-names = "default";
        pinctrl-0 = <0x00000080>;
        #address-cells = <0x00000001>;
        #size-cells = <0x00000000>;
        status = "disabled";
    };
    phy@e220 {
        compatible = "rockchip,rk3399-pcie-phy";
        #phy-cells = <0x00000000>;
        rockchip,grf = <0x00000015>;
        clocks = <0x00000008 0x0000008a>;
        clock-names = "refclk";
        resets = <0x00000008 0x00000087>;
        reset-names = "phy";
        status = "okay";
        linux,phandle = <0x00000083>;
        phandle = <0x00000083>;
    };
    pcie@f8000000 {
        compatible = "rockchip,rk3399-pcie";
        #address-cells = <0x00000003>;
        #size-cells = <0x00000002>;
        aspm-no-l0s;
        clocks = <0x00000008 0x000000c5 0x00000008 0x000000c4 0x00000008 0x00000147 0x00000008 0x000000a0>;
        clock-names = "aclk", "aclk-perf", "hclk", "pm";
        bus-range = <0x00000000 0x00000001>;
        max-link-speed = <0x00000001>;
        linux,pci-domain = <0x00000000>;
        msi-map = <0x00000000 0x00000081 0x00000000 0x00001000>;
        interrupts = <0x00000000 0x00000031 0x00000004 0x00000000 0x00000000 0x00000032 0x00000004 0x00000000 0x00000000 0x00000033 0x00000004 0x00000000>;
        interrupt-names = "sys", "legacy", "client";
        #interrupt-cells = <0x00000001>;
        interrupt-map-mask = <0x00000000 0x00000000 0x00000000 0x00000007>;
        interrupt-map = <0x00000000 0x00000000 0x00000000 0x00000001 0x00000082 0x00000000 0x00000000 0x00000000 0x00000000 0x00000002 0x00000082 0x00000001 0x00000000 0x00000000 0x00000000 0x00000003 0x00000082 0x00000002 0x00000000 0x00000000 0x00000000 0x00000004 0x00000082 0x00000003>;
        phys = <0x00000083>;
        phy-names = "pcie-phy";
        ranges = <0x82000000 0x00000000 0xfa000000 0x00000000 0xfa000000 0x00000000 0x00600000 0x81000000 0x00000000 0xfa600000 0x00000000 0xfa600000 0x00000000 0x00100000>;
        reg = <0x00000000 0xf8000000 0x00000000 0x02000000 0x00000000 0xfd000000 0x00000000 0x01000000>;
        reg-names = "axi-base", "apb-base";
        resets = <0x00000008 0x00000082 0x00000008 0x00000083 0x00000008 0x00000084 0x00000008 0x00000085 0x00000008 0x00000086 0x00000008 0x00000081 0x00000008 0x00000080>;
        reset-names = "core", "mgmt", "mgmt-sticky", "pipe", "pm", "pclk", "aclk";
        status = "okay";
        ep-gpios = <0x0000007e 0x0000000d 0x00000000>;
        num-lanes = <0x00000004>;
        pinctrl-names = "default";
        pinctrl-0 = <0x00000084>;
        interrupt-controller {
            interrupt-controller;
            #address-cells = <0x00000000>;
            #interrupt-cells = <0x00000001>;
            linux,phandle = <0x00000082>;
            phandle = <0x00000082>;
        };
    };
    pwm@ff420000 {
        compatible = "rockchip,rk3399-pwm", "rockchip,rk3288-pwm";
        reg = <0x00000000 0xff420000 0x00000000 0x00000010>;
        #pwm-cells = <0x00000003>;
        pinctrl-names = "default";
        pinctrl-0 = <0x00000085>;
        clocks = <0x00000032 0x0000001e>;
        clock-names = "pwm";
        status = "disabled";
    };
    pwm@ff420010 {
        compatible = "rockchip,rk3399-pwm", "rockchip,rk3288-pwm";
        reg = <0x00000000 0xff420010 0x00000000 0x00000010>;
        #pwm-cells = <0x00000003>;
        pinctrl-names = "default";
        pinctrl-0 = <0x00000086>;
        clocks = <0x00000032 0x0000001e>;
        clock-names = "pwm";
        status = "disabled";
    };
    pwm@ff420020 {
        compatible = "rockchip,rk3399-pwm", "rockchip,rk3288-pwm";
        reg = <0x00000000 0xff420020 0x00000000 0x00000010>;
        #pwm-cells = <0x00000003>;
        pinctrl-names = "default";
        pinctrl-0 = <0x00000087>;
        clocks = <0x00000032 0x0000001e>;
        clock-names = "pwm";
        status = "okay";
        linux,phandle = <0x000000d0>;
        phandle = <0x000000d0>;
    };
    pwm@ff420030 {
        compatible = "rockchip,rk3399-pwm", "rockchip,rk3288-pwm";
        reg = <0x00000000 0xff420030 0x00000000 0x00000010>;
        #pwm-cells = <0x00000003>;
        pinctrl-names = "default";
        pinctrl-0 = <0x00000088>;
        clocks = <0x00000032 0x0000001e>;
        clock-names = "pwm";
        status = "disabled";
    };
    dfi@ff630000 {
        reg = <0x00000000 0xff630000 0x00000000 0x00004000>;
        compatible = "rockchip,rk3399-dfi";
        rockchip,pmu = <0x00000089>;
        clocks = <0x00000008 0x00000179>;
        clock-names = "pclk_ddr_mon";
        status = "disabled";
        linux,phandle = <0x0000008a>;
        phandle = <0x0000008a>;
    };
    dmc {
        compatible = "rockchip,rk3399-dmc";
        devfreq-events = <0x0000008a>;
        interrupts = <0x00000000 0x00000001 0x00000004 0x00000000>;
        clocks = <0x00000008 0x000000aa>;
        clock-names = "dmc_clk";
        ddr_timing = <0x0000008b>;
        status = "disabled";
        operating-points-v2 = <0x0000008c>;
    };
    vpu_service@ff650000 {
        compatible = "rockchip,vpu_service";
        rockchip,grf = <0x00000015>;
        iommus = <0x0000008d>;
        iommu_enabled = <0x00000001>;
        reg = <0x00000000 0xff650000 0x00000000 0x00000800>;
        interrupts = <0x00000000 0x00000071 0x00000004 0x00000000 0x00000000 0x00000072 0x00000004 0x00000000>;
        interrupt-names = "irq_dec", "irq_enc";
        clocks = <0x00000008 0x000000eb 0x00000008 0x000001ea>;
        clock-names = "aclk_vcodec", "hclk_vcodec";
        resets = <0x00000008 0x00000053 0x00000008 0x00000051>;
        reset-names = "video_h", "video_a";
        power-domains = <0x0000001b 0x0000001f>;
        dev_mode = <0x00000000>;
        allocator = <0x00000001>;
        status = "okay";
    };
    iommu@ff650800 {
        compatible = "rockchip,iommu";
        reg = <0x00000000 0xff650800 0x00000000 0x00000040>;
        interrupts = <0x00000000 0x00000073 0x00000004 0x00000000>;
        interrupt-names = "vpu_mmu";
        clocks = <0x00000008 0x000000eb 0x00000008 0x000001ea>;
        clock-names = "aclk", "hclk";
        power-domains = <0x0000001b 0x0000001f>;
        #iommu-cells = <0x00000000>;
        linux,phandle = <0x0000008d>;
        phandle = <0x0000008d>;
    };
    rkvdec@ff660000 {
        compatible = "rockchip,rkvdec";
        rockchip,grf = <0x00000015>;
        iommus = <0x0000008e>;
        iommu_enabled = <0x00000001>;
        reg = <0x00000000 0xff660000 0x00000000 0x00000400>;
        interrupts = <0x00000000 0x00000074 0x00000004 0x00000000>;
        interrupt-names = "irq_dec";
        clocks = <0x00000008 0x000000ed 0x00000008 0x000001ec 0x00000008 0x0000009f 0x00000008 0x0000009e>;
        clock-names = "aclk_vcodec", "hclk_vcodec", "clk_cabac", "clk_core";
        resets = <0x00000008 0x0000005b 0x00000008 0x00000059>;
        reset-names = "video_h", "video_a";
        power-domains = <0x0000001b 0x00000020>;
        dev_mode = <0x00000002>;
        allocator = <0x00000001>;
        status = "okay";
    };
    iommu@ff660480 {
        compatible = "rockchip,iommu";
        reg = <0x00000000 0xff660480 0x00000000 0x00000040 0x00000000 0xff6604c0 0x00000000 0x00000040>;
        interrupts = <0x00000000 0x00000075 0x00000004 0x00000000>;
        interrupt-names = "vdec_mmu";
        clocks = <0x00000008 0x000000ed 0x00000008 0x000001ec>;
        clock-names = "aclk", "hclk";
        power-domains = <0x0000001b 0x00000020>;
        #iommu-cells = <0x00000000>;
        linux,phandle = <0x0000008e>;
        phandle = <0x0000008e>;
    };
    iep@ff670000 {
        compatible = "rockchip,iep";
        iommu_enabled = <0x00000001>;
        iommus = <0x0000008f>;
        reg = <0x00000000 0xff670000 0x00000000 0x00000800>;
        interrupts = <0x00000000 0x0000002a 0x00000004 0x00000000>;
        clocks = <0x00000008 0x000000e1 0x00000008 0x000001dd>;
        clock-names = "aclk_iep", "hclk_iep";
        power-domains = <0x0000001b 0x00000022>;
        allocator = <0x00000001>;
        version = <0x00000002>;
        status = "okay";
    };
    iommu@ff670800 {
        compatible = "rockchip,iommu";
        reg = <0x00000000 0xff670800 0x00000000 0x00000040>;
        interrupts = <0x00000000 0x0000002a 0x00000004 0x00000000>;
        interrupt-names = "iep_mmu";
        #iommu-cells = <0x00000000>;
        status = "okay";
        linux,phandle = <0x0000008f>;
        phandle = <0x0000008f>;
    };
    rga@ff680000 {
        compatible = "rockchip,rga2";
        reg = <0x00000000 0xff680000 0x00000000 0x00001000>;
        interrupts = <0x00000000 0x00000037 0x00000004 0x00000000>;
        interrupt-names = "rga";
        clocks = <0x00000008 0x000000dc 0x00000008 0x000001e5 0x00000008 0x0000006d>;
        clock-names = "aclk_rga", "hclk_rga", "clk_rga";
        resets = <0x00000008 0x0000006a 0x00000008 0x00000067 0x00000008 0x00000069>;
        reset-names = "core", "axi", "ahb";
        power-domains = <0x0000001b 0x00000021>;
        status = "okay";
        dev_mode = <0x00000001>;
        dma-coherent;
    };
    efuse@ff690000 {
        compatible = "rockchip,rk3399-efuse";
        reg = <0x00000000 0xff690000 0x00000000 0x00000080>;
        #address-cells = <0x00000001>;
        #size-cells = <0x00000001>;
        clocks = <0x00000008 0x0000017d>;
        clock-names = "pclk_efuse";
        id {
            reg = <0x00000007 0x00000010>;
            linux,phandle = <0x000000c1>;
            phandle = <0x000000c1>;
        };
        cpul-leakage {
            reg = <0x0000001a 0x00000001>;
        };
        cpub-leakage {
            reg = <0x00000017 0x00000001>;
        };
        gpu-leakage {
            reg = <0x00000018 0x00000001>;
        };
        center-leakage {
            reg = <0x00000019 0x00000001>;
        };
        logic-leakage {
            reg = <0x0000001b 0x00000001>;
        };
        wafer-info {
            reg = <0x0000001c 0x00000001>;
        };
    };
    pmu-clock-controller@ff750000 {
        compatible = "rockchip,rk3399-pmucru";
        reg = <0x00000000 0xff750000 0x00000000 0x00001000>;
        #clock-cells = <0x00000001>;
        #reset-cells = <0x00000001>;
        assigned-clocks = <0x00000032 0x00000001>;
        assigned-clock-rates = <0x284af100>;
        linux,phandle = <0x00000032>;
        phandle = <0x00000032>;
    };
    clock-controller@ff760000 {
        compatible = "rockchip,rk3399-cru";
        reg = <0x00000000 0xff760000 0x00000000 0x00001000>;
        #clock-cells = <0x00000001>;
        #reset-cells = <0x00000001>;
        assigned-clocks = <0x00000008 0x000000c0 0x00000008 0x000000c2 0x00000008 0x000001c2 0x00000008 0x0000004c 0x00000008 0x000000f0 0x00000008 0x000000cd 0x00000008 0x000001cd 0x00000008 0x0000009f 0x00000008 0x0000009e 0x00000008 0x000000f4 0x00000008 0x000000be 0x00000008 0x000000c9 0x00000008 0x00000186 0x00000008 0x000000d5 0x00000008 0x00000088 0x00000008 0x00000087 0x00000008 0x00000008 0x00000008 0x00000009 0x00000008 0x00000006 0x00000008 0x000000d0 0x00000008 0x00000005 0x00000008 0x000000c0 0x00000008 0x000001c0 0x00000008 0x00000140 0x00000008 0x000000c2 0x00000008 0x000001c1 0x00000008 0x00000142 0x00000008 0x000001c2 0x00000008 0x00000143 0x00000008 0x00000041 0x00000008 0x00000042 0x00000008 0x00000043 0x00000008 0x00000044 0x00000008 0x00000045 0x00000008 0x00000046 0x00000008 0x00000047 0x00000008 0x00000048 0x00000008 0x00000049 0x00000008 0x0000004a 0x00000008 0x0000004b 0x00000008 0x000000fa 0x00000008 0x000000e5 0x00000008 0x000000e6 0x00000008 0x0000006b 0x00000008 0x0000006c 0x00000008 0x0000016a 0x00000008 0x000000de 0x00000008 0x000000e3 0x00000008 0x000001cd 0x00000008 0x00000085 0x00000008 0x00000086 0x00000008 0x0000004e 0x00000008 0x000000f0 0x00000008 0x000000cd 0x00000008 0x000000e1 0x00000008 0x000000dc 0x00000008 0x0000006d 0x00000008 0x000000ed 0x00000008 0x000000eb 0x00000008 0x00000178 0x00000008 0x000000d5 0x00000008 0x0000009f 0x00000008 0x0000009e 0x00000008 0x000000f4 0x00000008 0x000000be 0x00000008 0x000000c9 0x00000008 0x00000186 0x00000008 0x00000088 0x00000008 0x00000087 0x00000008 0x000000d9 0x00000008 0x000001d9 0x00000008 0x000000db 0x00000008 0x000001db>;
        assigned-clock-rates = <0x047868c0 0x02faf080 0x02faf080 0x02faf080 0x02faf080 0x05f5e100 0x02faf080 0x08f0d180 0x08f0d180 0x08f0d180 0x02faf080 0x08f0d180 0x02faf080 0x05f5e100 0x047868c0 0x047868c0 0x30a32c00 0x30a32c00 0x23c34600 0x0bebc200 0x2faf0800 0x08f0d180 0x047868c0 0x023c3460 0x05f5e100 0x05f5e100 0x02faf080 0x05f5e100 0x02faf080 0x05f5e100 0x05f5e100 0x05f5e100 0x05f5e100 0x05f5e100 0x05f5e100 0x02faf080 0x02faf080 0x02faf080 0x02faf080 0x02faf080 0x0bebc200 0x17d78400 0x17d78400 0x05f5e100 0x05f5e100 0x05f5e100 0x17d78400 0x17d78400 0x0bebc200 0x05f5e100 0x0bebc200 0x0bebc200 0x05f5e100 0x17d78400 0x17d78400 0x17d78400 0x17d78400 0x11e1a300 0x17d78400 0x0bebc200 0x17d78400 0x11e1a300 0x11e1a300 0x11e1a300 0x11e1a300 0x11e1a300 0x05f5e100 0x08f0d180 0x08f0d180 0x17d78400 0x05f5e100 0x17d78400 0x05f5e100>;
        linux,phandle = <0x00000008>;
        phandle = <0x00000008>;
    };
    syscon@ff770000 {
        compatible = "rockchip,rk3399-grf", "syscon", "simple-mfd";
        reg = <0x00000000 0xff770000 0x00000000 0x00010000>;
        #address-cells = <0x00000001>;
        #size-cells = <0x00000001>;
        linux,phandle = <0x00000015>;
        phandle = <0x00000015>;
        io-domains {
            compatible = "rockchip,rk3399-io-voltage-domain";
            status = "okay";
            bt656-supply = <0x00000090>;
            audio-supply = <0x00000090>;
            sdmmc-supply = <0x00000020>;
            gpio1830-supply = <0x00000091>;
        };
        phy@f780 {
            compatible = "rockchip,rk3399-emmc-phy";
            reg = <0x0000f780 0x00000024>;
            clocks = <0x00000092>;
            clock-names = "emmcclk";
            #phy-cells = <0x00000000>;
            status = "okay";
            linux,phandle = <0x00000025>;
            phandle = <0x00000025>;
        };
        usb2-phy@e450 {
            compatible = "rockchip,rk3399-usb2phy";
            reg = <0x0000e450 0x00000010>;
            clocks = <0x00000008 0x0000007b>;
            clock-names = "phyclk";
            #clock-cells = <0x00000000>;
            clock-output-names = "clk_usbphy0_480m";
            status = "okay";
            otg-vbus-gpios = <0x0000001a 0x00000016 0x00000000>;
            linux,phandle = <0x00000028>;
            phandle = <0x00000028>;
            otg-port {
                #phy-cells = <0x00000000>;
                interrupts = <0x00000000 0x00000067 0x00000004 0x00000000 0x00000000 0x00000068 0x00000004 0x00000000 0x00000000 0x0000006a 0x00000004 0x00000000>;
                interrupt-names = "otg-bvalid", "otg-id", "linestate";
                status = "okay";
                linux,phandle = <0x00000029>;
                phandle = <0x00000029>;
            };
            host-port {
                #phy-cells = <0x00000000>;
                interrupts = <0x00000000 0x0000001b 0x00000004 0x00000000>;
                interrupt-names = "linestate";
                status = "okay";
                phy-supply = <0x00000093>;
                linux,phandle = <0x00000026>;
                phandle = <0x00000026>;
            };
        };
        usb2-phy@e460 {
            compatible = "rockchip,rk3399-usb2phy";
            reg = <0x0000e460 0x00000010>;
            clocks = <0x00000008 0x0000007c>;
            clock-names = "phyclk";
            #clock-cells = <0x00000000>;
            clock-output-names = "clk_usbphy1_480m";
            status = "okay";
            otg-port {
                #phy-cells = <0x00000000>;
                interrupts = <0x00000000 0x0000006c 0x00000004 0x00000000 0x00000000 0x0000006d 0x00000004 0x00000000 0x00000000 0x0000006f 0x00000004 0x00000000>;
                interrupt-names = "otg-bvalid", "otg-id", "linestate";
                status = "okay";
                linux,phandle = <0x0000002b>;
                phandle = <0x0000002b>;
            };
            host-port {
                #phy-cells = <0x00000000>;
                interrupts = <0x00000000 0x0000001f 0x00000004 0x00000000>;
                interrupt-names = "linestate";
                status = "okay";
                phy-supply = <0x00000093>;
                linux,phandle = <0x00000027>;
                phandle = <0x00000027>;
            };
        };
        pvtm {
            compatible = "rockchip,rk3399-pvtm";
            clocks = <0x00000008 0x00000073 0x00000008 0x00000074 0x00000008 0x00000075 0x00000008 0x00000076>;
            clock-names = "core_l", "core_b", "gpu", "ddr";
            status = "okay";
        };
    };
    phy@ff7c0000 {
        compatible = "rockchip,rk3399-typec-phy";
        reg = <0x00000000 0xff7c0000 0x00000000 0x00040000>;
        rockchip,grf = <0x00000015>;
        #phy-cells = <0x00000001>;
        clocks = <0x00000008 0x0000007e 0x00000008 0x0000007d>;
        clock-names = "tcpdcore", "tcpdphy-ref";
        assigned-clocks = <0x00000008 0x0000007e>;
        assigned-clock-rates = <0x02faf080>;
        power-domains = <0x0000001b 0x00000008>;
        resets = <0x00000008 0x00000095 0x00000008 0x00000094 0x00000008 0x0000014c>;
        reset-names = "uphy", "uphy-pipe", "uphy-tcphy";
        rockchip,typec-conn-dir = <0x0000e580 0x00000000 0x00000010>;
        rockchip,usb3tousb2-en = <0x0000e580 0x00000003 0x00000013>;
        rockchip,usb3-host-disable = <0x00002434 0x00000000 0x00000010>;
        rockchip,usb3-host-port = <0x00002434 0x0000000c 0x0000001c>;
        rockchip,external-psm = <0x0000e588 0x0000000e 0x0000001e>;
        rockchip,pipe-status = <0x0000e5c0 0x00000000 0x00000000>;
        rockchip,uphy-dp-sel = <0x00006268 0x00000013 0x00000013>;
        status = "okay";
        extcon = <0x0000002f>;
        dp-port {
            #phy-cells = <0x00000000>;
            linux,phandle = <0x0000002d>;
            phandle = <0x0000002d>;
        };
        usb3-port {
            #phy-cells = <0x00000000>;
            linux,phandle = <0x0000002a>;
            phandle = <0x0000002a>;
        };
    };
    phy@ff800000 {
        compatible = "rockchip,rk3399-typec-phy";
        reg = <0x00000000 0xff800000 0x00000000 0x00040000>;
        rockchip,grf = <0x00000015>;
        #phy-cells = <0x00000001>;
        clocks = <0x00000008 0x00000080 0x00000008 0x0000007f>;
        clock-names = "tcpdcore", "tcpdphy-ref";
        assigned-clocks = <0x00000008 0x00000080>;
        assigned-clock-rates = <0x02faf080>;
        power-domains = <0x0000001b 0x00000009>;
        resets = <0x00000008 0x0000009d 0x00000008 0x0000009c 0x00000008 0x0000014d>;
        reset-names = "uphy", "uphy-pipe", "uphy-tcphy";
        rockchip,typec-conn-dir = <0x0000e58c 0x00000000 0x00000010>;
        rockchip,usb3tousb2-en = <0x0000e58c 0x00000003 0x00000013>;
        rockchip,usb3-host-disable = <0x00002444 0x00000000 0x00000010>;
        rockchip,usb3-host-port = <0x00002444 0x0000000c 0x0000001c>;
        rockchip,external-psm = <0x0000e594 0x0000000e 0x0000001e>;
        rockchip,pipe-status = <0x0000e5c0 0x00000010 0x00000010>;
        rockchip,uphy-dp-sel = <0x00006268 0x00000003 0x00000013>;
        status = "okay";
        dp-port {
            #phy-cells = <0x00000000>;
            linux,phandle = <0x0000002e>;
            phandle = <0x0000002e>;
        };
        usb3-port {
            #phy-cells = <0x00000000>;
            linux,phandle = <0x0000002c>;
            phandle = <0x0000002c>;
        };
    };
    watchdog@ff848000 {
        compatible = "snps,dw-wdt";
        reg = <0x00000000 0xff848000 0x00000000 0x00000100>;
        clocks = <0x00000008 0x0000017c>;
        interrupts = <0x00000000 0x00000078 0x00000004 0x00000000>;
    };
    rktimer@ff850000 {
        compatible = "rockchip,rk3399-timer";
        reg = <0x00000000 0xff850000 0x00000000 0x00001000>;
        interrupts = <0x00000000 0x00000051 0x00000004 0x00000000>;
        clocks = <0x00000008 0x00000168 0x00000008 0x0000005a>;
        clock-names = "pclk", "timer";
    };
    spdif@ff870000 {
        compatible = "rockchip,rk3399-spdif";
        reg = <0x00000000 0xff870000 0x00000000 0x00001000>;
        interrupts = <0x00000000 0x00000042 0x00000004 0x00000000>;
        dmas = <0x00000094 0x00000007>;
        dma-names = "tx";
        clock-names = "mclk", "hclk";
        clocks = <0x00000008 0x00000055 0x00000008 0x000001d7>;
        pinctrl-names = "default";
        pinctrl-0 = <0x00000095>;
        power-domains = <0x0000001b 0x0000001c>;
        status = "okay";
        assigned-clocks = <0x00000008 0x000000b1>;
        assigned-clock-parents = <0x00000008 0x00000005>;
        #sound-dai-cells = <0x00000000>;
        linux,phandle = <0x000000d1>;
        phandle = <0x000000d1>;
    };
    i2s@ff880000 {
        compatible = "rockchip,rk3399-i2s", "rockchip,rk3066-i2s";
        reg = <0x00000000 0xff880000 0x00000000 0x00001000>;
        rockchip,grf = <0x00000015>;
        interrupts = <0x00000000 0x00000027 0x00000004 0x00000000>;
        dmas = <0x00000094 0x00000000 0x00000094 0x00000001>;
        dma-names = "tx", "rx";
        clock-names = "i2s_clk", "i2s_hclk";
        clocks = <0x00000008 0x00000056 0x00000008 0x000001d4>;
        pinctrl-names = "default";
        pinctrl-0 = <0x00000096>;
        power-domains = <0x0000001b 0x0000001c>;
        status = "okay";
        assigned-clocks = <0x00000008 0x000000ae>;
        assigned-clock-parents = <0x00000008 0x00000005>;
        rockchip,i2s-broken-burst-len;
        rockchip,playback-channels = <0x00000008>;
        rockchip,capture-channels = <0x00000008>;
        #sound-dai-cells = <0x00000000>;
    };
    i2s@ff890000 {
        compatible = "rockchip,rk3399-i2s", "rockchip,rk3066-i2s";
        reg = <0x00000000 0xff890000 0x00000000 0x00001000>;
        interrupts = <0x00000000 0x00000028 0x00000004 0x00000000>;
        dmas = <0x00000094 0x00000002 0x00000094 0x00000003>;
        dma-names = "tx", "rx";
        clock-names = "i2s_clk", "i2s_hclk";
        clocks = <0x00000008 0x00000057 0x00000008 0x000001d5>;
        pinctrl-names = "default";
        pinctrl-0 = <0x00000097>;
        power-domains = <0x0000001b 0x0000001c>;
        status = "disabled";
        assigned-clocks = <0x00000008 0x000000af>;
        assigned-clock-parents = <0x00000008 0x00000005>;
    };
    i2s@ff8a0000 {
        compatible = "rockchip,rk3399-i2s", "rockchip,rk3066-i2s";
        reg = <0x00000000 0xff8a0000 0x00000000 0x00001000>;
        interrupts = <0x00000000 0x00000029 0x00000004 0x00000000>;
        dmas = <0x00000094 0x00000004 0x00000094 0x00000005>;
        dma-names = "tx", "rx";
        clock-names = "i2s_clk", "i2s_hclk";
        clocks = <0x00000008 0x00000058 0x00000008 0x000001d6>;
        power-domains = <0x0000001b 0x0000001c>;
        status = "okay";
        assigned-clocks = <0x00000008 0x000000b0>;
        assigned-clock-parents = <0x00000008 0x00000005>;
        #sound-dai-cells = <0x00000000>;
        linux,phandle = <0x000000cb>;
        phandle = <0x000000cb>;
    };
    gpu@ff9a0000 {
        compatible = "arm,malit860", "arm,malit86x", "arm,malit8xx", "arm,mali-midgard";
        reg = <0x00000000 0xff9a0000 0x00000000 0x00010000>;
        interrupts = <0x00000000 0x00000013 0x00000004 0x00000000 0x00000000 0x00000014 0x00000004 0x00000000 0x00000000 0x00000015 0x00000004 0x00000000>;
        interrupt-names = "GPU", "JOB", "MMU";
        clocks = <0x00000008 0x000000d0>;
        clock-names = "clk_mali";
        #cooling-cells = <0x00000002>;
        power-domains = <0x0000001b 0x00000023>;
        power-off-delay-ms = <0x000000c8>;
        status = "okay";
        operating-points-v2 = <0x00000098>;
        mali-supply = <0x00000099>;
        linux,phandle = <0x0000005d>;
        phandle = <0x0000005d>;
        power_model {
            compatible = "arm,mali-simple-power-model";
            voltage = <0x00000384>;
            frequency = <0x000001f4>;
            static-power = <0x0000012c>;
            dynamic-power = <0x0000018c>;
            ts = <0x00007d00 0x0000125c 0xffffffb0 0x00000002>;
            thermal-zone = "gpu-thermal";
        };
    };
    vop@ff8f0000 {
        compatible = "rockchip,rk3399-vop-lit";
        reg = <0x00000000 0xff8f0000 0x00000000 0x00001ffc 0x00000000 0xff8f2000 0x00000000 0x00000400>;
        interrupts = <0x00000000 0x00000077 0x00000004 0x00000000>;
        clocks = <0x00000008 0x000000db 0x00000008 0x000000b5 0x00000008 0x000001db>;
        clock-names = "aclk_vop", "dclk_vop", "hclk_vop";
        resets = <0x00000008 0x00000113 0x00000008 0x00000117 0x00000008 0x00000119>;
        reset-names = "axi", "ahb", "dclk";
        power-domains = <0x0000001b 0x00000012>;
        iommus = <0x0000009a>;
        status = "okay";
        assigned-clocks = <0x00000008 0x000000b7>;
        assigned-clock-parents = <0x00000008 0x00000004>;
        port {
            #address-cells = <0x00000001>;
            #size-cells = <0x00000000>;
            linux,phandle = <0x000000af>;
            phandle = <0x000000af>;
            endpoint@0 {
                reg = <0x00000000>;
                remote-endpoint = <0x0000009b>;
                linux,phandle = <0x000000aa>;
                phandle = <0x000000aa>;
            };
            endpoint@1 {
                reg = <0x00000001>;
                remote-endpoint = <0x0000009c>;
                linux,phandle = <0x000000ad>;
                phandle = <0x000000ad>;
            };
            endpoint@2 {
                reg = <0x00000002>;
                remote-endpoint = <0x0000009d>;
                linux,phandle = <0x000000a8>;
                phandle = <0x000000a8>;
            };
            endpoint@3 {
                reg = <0x00000003>;
                remote-endpoint = <0x0000009e>;
                linux,phandle = <0x00000031>;
                phandle = <0x00000031>;
            };
        };
    };
    voppwm@ff8f01a0 {
        compatible = "rockchip,vop-pwm";
        reg = <0x00000000 0xff8f01a0 0x00000000 0x00000010>;
        #pwm-cells = <0x00000003>;
        pinctrl-names = "default";
        pinctrl-0 = <0x0000009f>;
        clocks = <0x00000008 0x0000006c>;
        clock-names = "pwm";
        status = "disabled";
    };
    iommu@ff8f3f00 {
        compatible = "rockchip,iommu";
        reg = <0x00000000 0xff8f3f00 0x00000000 0x00000100>;
        interrupts = <0x00000000 0x00000077 0x00000004 0x00000000>;
        interrupt-names = "vopl_mmu";
        clocks = <0x00000008 0x000000db 0x00000008 0x000001db>;
        clock-names = "aclk", "hclk";
        power-domains = <0x0000001b 0x00000012>;
        #iommu-cells = <0x00000000>;
        status = "okay";
        linux,phandle = <0x0000009a>;
        phandle = <0x0000009a>;
    };
    vop@ff900000 {
        compatible = "rockchip,rk3399-vop-big";
        reg = <0x00000000 0xff900000 0x00000000 0x00001ffc 0x00000000 0xff902000 0x00000000 0x00001000>;
        interrupts = <0x00000000 0x00000076 0x00000004 0x00000000>;
        clocks = <0x00000008 0x000000d9 0x00000008 0x000000b4 0x00000008 0x000001d9>;
        clock-names = "aclk_vop", "dclk_vop", "hclk_vop";
        resets = <0x00000008 0x00000112 0x00000008 0x00000116 0x00000008 0x00000118>;
        reset-names = "axi", "ahb", "dclk";
        power-domains = <0x0000001b 0x00000011>;
        iommus = <0x000000a0>;
        status = "okay";
        assigned-clocks = <0x00000008 0x000000b6>;
        assigned-clock-parents = <0x00000008 0x00000007>;
        port {
            #address-cells = <0x00000001>;
            #size-cells = <0x00000000>;
            linux,phandle = <0x000000ae>;
            phandle = <0x000000ae>;
            endpoint@0 {
                reg = <0x00000000>;
                remote-endpoint = <0x000000a1>;
                linux,phandle = <0x000000ac>;
                phandle = <0x000000ac>;
            };
            endpoint@1 {
                reg = <0x00000001>;
                remote-endpoint = <0x000000a2>;
                linux,phandle = <0x000000a9>;
                phandle = <0x000000a9>;
            };
            endpoint@2 {
                reg = <0x00000002>;
                remote-endpoint = <0x000000a3>;
                linux,phandle = <0x000000a7>;
                phandle = <0x000000a7>;
            };
            endpoint@3 {
                reg = <0x00000003>;
                remote-endpoint = <0x000000a4>;
                linux,phandle = <0x00000030>;
                phandle = <0x00000030>;
            };
        };
    };
    voppwm@ff9001a0 {
        compatible = "rockchip,vop-pwm";
        reg = <0x00000000 0xff9001a0 0x00000000 0x00000010>;
        #pwm-cells = <0x00000003>;
        pinctrl-names = "default";
        pinctrl-0 = <0x000000a5>;
        clocks = <0x00000008 0x0000006b>;
        clock-names = "pwm";
        status = "disabled";
    };
    iommu@ff903f00 {
        compatible = "rockchip,iommu";
        reg = <0x00000000 0xff903f00 0x00000000 0x00000100>;
        interrupts = <0x00000000 0x00000076 0x00000004 0x00000000>;
        interrupt-names = "vopb_mmu";
        clocks = <0x00000008 0x000000d9 0x00000008 0x000001d9>;
        clock-names = "aclk", "hclk";
        power-domains = <0x0000001b 0x00000011>;
        #iommu-cells = <0x00000000>;
        status = "okay";
        linux,phandle = <0x000000a0>;
        phandle = <0x000000a0>;
    };
    iommu@ff914000 {
        compatible = "rockchip,iommu";
        reg = <0x00000000 0xff914000 0x00000000 0x00000100 0x00000000 0xff915000 0x00000000 0x00000100>;
        interrupts = <0x00000000 0x0000002b 0x00000004 0x00000000>;
        interrupt-names = "isp0_mmu";
        #iommu-cells = <0x00000000>;
        clocks = <0x00000008 0x000000e7 0x00000008 0x000001e1>;
        clock-names = "aclk", "hclk";
        power-domains = <0x0000001b 0x00000013>;
        rk_iommu,disable_reset_quirk;
        status = "disabled";
        linux,phandle = <0x000000c9>;
        phandle = <0x000000c9>;
    };
    iommu@ff924000 {
        compatible = "rockchip,iommu";
        reg = <0x00000000 0xff924000 0x00000000 0x00000100 0x00000000 0xff925000 0x00000000 0x00000100>;
        interrupts = <0x00000000 0x0000002c 0x00000004 0x00000000>;
        interrupt-names = "isp1_mmu";
        #iommu-cells = <0x00000000>;
        clocks = <0x00000008 0x000000e8 0x00000008 0x000001e2>;
        clock-names = "aclk", "hclk";
        power-domains = <0x0000001b 0x00000014>;
        rk_iommu,disable_reset_quirk;
        status = "disabled";
        linux,phandle = <0x000000ca>;
        phandle = <0x000000ca>;
    };
    hdmi@ff940000 {
        compatible = "rockchip,rk3399-dw-hdmi";
        reg = <0x00000000 0xff940000 0x00000000 0x00020000>;
        reg-io-width = <0x00000004>;
        rockchip,grf = <0x00000015>;
        pinctrl-names = "default";
        pinctrl-0 = <0x000000a6>;
        power-domains = <0x0000001b 0x00000015>;
        interrupts = <0x00000000 0x00000017 0x00000004 0x00000000>;
        clocks = <0x00000008 0x00000174 0x00000008 0x00000071 0x00000008 0x00000007 0x00000008 0x0000016f>;
        clock-names = "iahb", "isfr", "vpll", "grf";
        status = "okay";
        #address-cells = <0x00000001>;
        #size-cells = <0x00000000>;
        #sound-dai-cells = <0x00000000>;
        ddc-i2c-scl-high-time-ns = <0x00002599>;
        ddc-i2c-scl-low-time-ns = <0x00002710>;
        rockchip,phy-table = <0x046cf710 0x00008009 0x00000004 0x00000272 0x09d5b340 0x0000802b 0x00000004 0x00000209 0x11b3dc40 0x0000802d 0x00000005 0x000000ed 0x2367b880 0x0000803d 0x00000000 0x0000002d 0x00000000 0x00000000 0x00000000 0x00000000>;
        rockchip,hdmi_video_source = <0x00000000>;
        linux,phandle = <0x000000cc>;
        phandle = <0x000000cc>;
        ports {
            port {
                #address-cells = <0x00000001>;
                #size-cells = <0x00000000>;
                endpoint@0 {
                    reg = <0x00000000>;
                    remote-endpoint = <0x000000a7>;
                    linux,phandle = <0x000000a3>;
                    phandle = <0x000000a3>;
                };
                endpoint@1 {
                    reg = <0x00000001>;
                    remote-endpoint = <0x000000a8>;
                    status = "disabled";
                    linux,phandle = <0x0000009d>;
                    phandle = <0x0000009d>;
                };
            };
        };
    };
    hdmihdcp2@ff988000 {
        compatible = "rockchip,rk3399-hdmi-hdcp2";
        reg = <0x00000000 0xff988000 0x00000000 0x00002000>;
        interrupts = <0x00000000 0x00000016 0x00000004>;
        clocks = <0x00000008 0x000000e0 0x00000008 0x00000176 0x00000008 0x000001e9>;
        clock-names = "aclk_hdcp2", "pclk_hdcp2", "hdcp2_clk_hdmi";
        status = "okay";
    };
    mipi@ff960000 {
        compatible = "rockchip,rk3399-mipi-dsi", "snps,dw-mipi-dsi";
        reg = <0x00000000 0xff960000 0x00000000 0x00008000>;
        interrupts = <0x00000000 0x0000002d 0x00000004 0x00000000>;
        clocks = <0x00000008 0x00000077 0x00000008 0x00000170 0x00000008 0x000000a3>;
        clock-names = "ref", "pclk", "phy_cfg";
        power-domains = <0x0000001b 0x0000000f>;
        rockchip,grf = <0x00000015>;
        #address-cells = <0x00000001>;
        #size-cells = <0x00000000>;
        status = "disabled";
        ports {
            #address-cells = <0x00000001>;
            #size-cells = <0x00000000>;
            reg = <0x00000001>;
            port {
                #address-cells = <0x00000001>;
                #size-cells = <0x00000000>;
                endpoint@0 {
                    reg = <0x00000000>;
                    remote-endpoint = <0x000000a9>;
                    linux,phandle = <0x000000a2>;
                    phandle = <0x000000a2>;
                };
                endpoint@1 {
                    reg = <0x00000001>;
                    remote-endpoint = <0x000000aa>;
                    linux,phandle = <0x0000009b>;
                    phandle = <0x0000009b>;
                };
            };
        };
    };
    edp@ff970000 {
        compatible = "rockchip,rk3399-edp";
        reg = <0x00000000 0xff970000 0x00000000 0x00008000>;
        interrupts = <0x00000000 0x0000000a 0x00000004 0x00000000>;
        clocks = <0x00000008 0x0000016a 0x00000008 0x0000016c>;
        clock-names = "dp", "pclk";
        power-domains = <0x0000001b 0x00000019>;
        resets = <0x00000008 0x0000011d>;
        reset-names = "dp";
        rockchip,grf = <0x00000015>;
        status = "disabled";
        pinctrl-names = "default";
        pinctrl-0 = <0x000000ab>;
        ports {
            #address-cells = <0x00000001>;
            #size-cells = <0x00000000>;
            port@0 {
                reg = <0x00000000>;
                #address-cells = <0x00000001>;
                #size-cells = <0x00000000>;
                endpoint@0 {
                    reg = <0x00000000>;
                    remote-endpoint = <0x000000ac>;
                    linux,phandle = <0x000000a1>;
                    phandle = <0x000000a1>;
                };
                endpoint@1 {
                    reg = <0x00000001>;
                    remote-endpoint = <0x000000ad>;
                    linux,phandle = <0x0000009c>;
                    phandle = <0x0000009c>;
                };
            };
        };
    };
    display-subsystem {
        compatible = "rockchip,display-subsystem";
        ports = <0x000000ae 0x000000af>;
        status = "okay";
        memory-region = <0x000000b0>;
        route {
            route-hdmi {
                video,vrefresh = <0x00000000>;
                video,vdisplay = <0x00000000>;
                video,hdisplay = <0x00000000>;
                logo,ymirror = <0x00000001>;
                logo,bpp = <0x00000018>;
                logo,height = <0x00000438>;
                logo,width = <0x00000780>;
                logo,offset = <0x00000036>;
                status = "okay";
                logo,uboot = "logo.bmp";
                logo,kernel = "logo_kernel.bmp";
                logo,mode = "fullscreen";
                charge_logo,mode = "center";
                connect = <0x000000a7>;
            };
            route-mipi {
                status = "disabled";
                logo,uboot = "logo.bmp";
                logo,kernel = "logo_kernel.bmp";
                logo,mode = "fullscreen";
                charge_logo,mode = "center";
                connect = <0x000000a9>;
            };
            route-edp {
                status = "disabled";
                logo,uboot = "logo.bmp";
                logo,kernel = "logo_kernel.bmp";
                logo,mode = "fullscreen";
                charge_logo,mode = "center";
                connect = <0x000000ac>;
            };
        };
    };
    pinctrl {
        compatible = "rockchip,rk3399-pinctrl";
        rockchip,grf = <0x00000015>;
        rockchip,pmu = <0x00000089>;
        #address-cells = <0x00000002>;
        #size-cells = <0x00000002>;
        ranges;
        pinctrl-names = "default", "sleep";
        pinctrl-0 = <0x000000b1 0x000000b2 0x000000b3>;
        pinctrl-1 = <0x000000b4 0x000000b5>;
        gpio0@ff720000 {
            compatible = "rockchip,gpio-bank";
            reg = <0x00000000 0xff720000 0x00000000 0x00000100>;
            clocks = <0x00000032 0x00000017>;
            interrupts = <0x00000000 0x0000000e 0x00000004 0x00000000>;
            gpio-controller;
            #gpio-cells = <0x00000002>;
            interrupt-controller;
            #interrupt-cells = <0x00000002>;
            linux,phandle = <0x0000007e>;
            phandle = <0x0000007e>;
        };
        gpio1@ff730000 {
            compatible = "rockchip,gpio-bank";
            reg = <0x00000000 0xff730000 0x00000000 0x00000100>;
            clocks = <0x00000032 0x00000018>;
            interrupts = <0x00000000 0x0000000f 0x00000004 0x00000000>;
            gpio-controller;
            #gpio-cells = <0x00000002>;
            interrupt-controller;
            #interrupt-cells = <0x00000002>;
            linux,phandle = <0x0000001a>;
            phandle = <0x0000001a>;
        };
        gpio2@ff780000 {
            compatible = "rockchip,gpio-bank";
            reg = <0x00000000 0xff780000 0x00000000 0x00000100>;
            clocks = <0x00000008 0x00000150>;
            interrupts = <0x00000000 0x00000010 0x00000004 0x00000000>;
            gpio-controller;
            #gpio-cells = <0x00000002>;
            interrupt-controller;
            #interrupt-cells = <0x00000002>;
        };
        gpio3@ff788000 {
            compatible = "rockchip,gpio-bank";
            reg = <0x00000000 0xff788000 0x00000000 0x00000100>;
            clocks = <0x00000008 0x00000151>;
            interrupts = <0x00000000 0x00000011 0x00000004 0x00000000>;
            gpio-controller;
            #gpio-cells = <0x00000002>;
            interrupt-controller;
            #interrupt-cells = <0x00000002>;
            linux,phandle = <0x00000017>;
            phandle = <0x00000017>;
        };
        gpio4@ff790000 {
            compatible = "rockchip,gpio-bank";
            reg = <0x00000000 0xff790000 0x00000000 0x00000100>;
            clocks = <0x00000008 0x00000152>;
            interrupts = <0x00000000 0x00000012 0x00000004 0x00000000>;
            gpio-controller;
            #gpio-cells = <0x00000002>;
            interrupt-controller;
            #interrupt-cells = <0x00000002>;
            linux,phandle = <0x000000d7>;
            phandle = <0x000000d7>;
        };
        pcfg-pull-up {
            bias-pull-up;
            linux,phandle = <0x000000b6>;
            phandle = <0x000000b6>;
        };
        pcfg-pull-down {
            bias-pull-down;
            linux,phandle = <0x000000c0>;
            phandle = <0x000000c0>;
        };
        pcfg-pull-none {
            bias-disable;
            linux,phandle = <0x000000b8>;
            phandle = <0x000000b8>;
        };
        pcfg-pull-up-20ma {
            bias-pull-up;
            drive-strength = <0x00000014>;
            linux,phandle = <0x000000bb>;
            phandle = <0x000000bb>;
        };
        pcfg-pull-none-20ma {
            bias-disable;
            drive-strength = <0x00000014>;
            linux,phandle = <0x000000bc>;
            phandle = <0x000000bc>;
        };
        pcfg-pull-none-18ma {
            bias-disable;
            drive-strength = <0x00000012>;
            linux,phandle = <0x000000be>;
            phandle = <0x000000be>;
        };
        pcfg-pull-none-12ma {
            bias-disable;
            drive-strength = <0x0000000c>;
            linux,phandle = <0x000000ba>;
            phandle = <0x000000ba>;
        };
        pcfg-pull-up-8ma {
            bias-pull-up;
            drive-strength = <0x00000008>;
            linux,phandle = <0x000000bd>;
            phandle = <0x000000bd>;
        };
        pcfg-pull-down-4ma {
            bias-pull-down;
            drive-strength = <0x00000004>;
        };
        pcfg-pull-up-2ma {
            bias-pull-up;
            drive-strength = <0x00000002>;
        };
        pcfg-pull-down-12ma {
            bias-pull-down;
            drive-strength = <0x0000000c>;
        };
        pcfg-pull-none-13ma {
            bias-disable;
            drive-strength = <0x0000000d>;
            linux,phandle = <0x000000b7>;
            phandle = <0x000000b7>;
        };
        pcfg-output-high {
            output-high;
            linux,phandle = <0x000000bf>;
            phandle = <0x000000bf>;
        };
        pcfg-output-low {
            output-low;
            linux,phandle = <0x000000b9>;
            phandle = <0x000000b9>;
        };
        pcfg-input {
            input-enable;
        };
        emmc {
            emmc-pwr {
                rockchip,pins = <0x00000000 0x00000005 0x00000001 0x000000b6>;
            };
        };
        gmac {
            rgmii-pins {
                rockchip,pins = <0x00000003 0x00000011 0x00000001 0x000000b7 0x00000003 0x0000000e 0x00000001 0x000000b8 0x00000003 0x0000000d 0x00000001 0x000000b8 0x00000003 0x0000000c 0x00000001 0x000000b7 0x00000003 0x0000000b 0x00000001 0x000000b8 0x00000003 0x00000009 0x00000001 0x000000b8 0x00000003 0x00000008 0x00000001 0x000000b8 0x00000003 0x00000007 0x00000001 0x000000b8 0x00000003 0x00000006 0x00000001 0x000000b8 0x00000003 0x00000005 0x00000001 0x000000b7 0x00000003 0x00000004 0x00000001 0x000000b7 0x00000003 0x00000003 0x00000001 0x000000b8 0x00000003 0x00000002 0x00000001 0x000000b8 0x00000003 0x00000001 0x00000001 0x000000b7 0x00000003 0x00000000 0x00000001 0x000000b7>;
                linux,phandle = <0x00000019>;
                phandle = <0x00000019>;
            };
            rmii-pins {
                rockchip,pins = <0x00000003 0x0000000d 0x00000001 0x000000b8 0x00000003 0x0000000c 0x00000001 0x000000b7 0x00000003 0x0000000b 0x00000001 0x000000b8 0x00000003 0x0000000a 0x00000001 0x000000b8 0x00000003 0x00000009 0x00000001 0x000000b8 0x00000003 0x00000008 0x00000001 0x000000b8 0x00000003 0x00000007 0x00000001 0x000000b8 0x00000003 0x00000006 0x00000001 0x000000b8 0x00000003 0x00000005 0x00000001 0x000000b7 0x00000003 0x00000004 0x00000001 0x000000b7>;
            };
            rgmii-sleep-pins {
                rockchip,pins = <0x00000003 0x0000000f 0x00000000 0x000000b9>;
            };
        };
        i2c0 {
            i2c0-xfer {
                rockchip,pins = <0x00000001 0x0000000f 0x00000002 0x000000b8 0x00000001 0x00000010 0x00000002 0x000000b8>;
                linux,phandle = <0x00000033>;
                phandle = <0x00000033>;
            };
        };
        i2c1 {
            i2c1-xfer {
                rockchip,pins = <0x00000004 0x00000002 0x00000001 0x000000b8 0x00000004 0x00000001 0x00000001 0x000000b8>;
                linux,phandle = <0x0000003a>;
                phandle = <0x0000003a>;
            };
        };
        i2c2 {
            i2c2-xfer {
                rockchip,pins = <0x00000002 0x00000001 0x00000002 0x000000ba 0x00000002 0x00000000 0x00000002 0x000000ba>;
                linux,phandle = <0x0000003b>;
                phandle = <0x0000003b>;
            };
        };
        i2c3 {
            i2c3-xfer {
                rockchip,pins = <0x00000004 0x00000011 0x00000001 0x000000b8 0x00000004 0x00000010 0x00000001 0x000000b8>;
                linux,phandle = <0x0000003c>;
                phandle = <0x0000003c>;
            };
            i2c3_gpio {
                rockchip,pins = <0x00000004 0x00000011 0x00000000 0x000000b8 0x00000004 0x00000010 0x00000000 0x000000b8>;
            };
        };
        i2c4 {
            i2c4-xfer {
                rockchip,pins = <0x00000001 0x0000000c 0x00000001 0x000000b8 0x00000001 0x0000000b 0x00000001 0x000000b8>;
                linux,phandle = <0x0000007d>;
                phandle = <0x0000007d>;
            };
        };
        i2c5 {
            i2c5-xfer {
                rockchip,pins = <0x00000003 0x0000000b 0x00000002 0x000000b8 0x00000003 0x0000000a 0x00000002 0x000000b8>;
                linux,phandle = <0x0000003d>;
                phandle = <0x0000003d>;
            };
        };
        i2c6 {
            i2c6-xfer {
                rockchip,pins = <0x00000002 0x0000000a 0x00000002 0x000000b8 0x00000002 0x00000009 0x00000002 0x000000b8>;
                linux,phandle = <0x0000003e>;
                phandle = <0x0000003e>;
            };
        };
        i2c7 {
            i2c7-xfer {
                rockchip,pins = <0x00000002 0x00000008 0x00000002 0x000000b8 0x00000002 0x00000007 0x00000002 0x000000b8>;
                linux,phandle = <0x0000003f>;
                phandle = <0x0000003f>;
            };
        };
        i2c8 {
            i2c8-xfer {
                rockchip,pins = <0x00000001 0x00000015 0x00000001 0x000000b8 0x00000001 0x00000014 0x00000001 0x000000b8>;
                linux,phandle = <0x00000080>;
                phandle = <0x00000080>;
            };
        };
        i2s0 {
            i2s0-8ch-bus {
                rockchip,pins = <0x00000003 0x00000018 0x00000001 0x000000b8 0x00000003 0x00000019 0x00000001 0x000000b8 0x00000003 0x0000001a 0x00000001 0x000000b8 0x00000003 0x0000001b 0x00000001 0x000000b8 0x00000003 0x0000001c 0x00000001 0x000000b8 0x00000003 0x0000001d 0x00000001 0x000000b8 0x00000003 0x0000001e 0x00000001 0x000000b8 0x00000003 0x0000001f 0x00000001 0x000000b8 0x00000004 0x00000000 0x00000001 0x000000b8>;
                linux,phandle = <0x00000096>;
                phandle = <0x00000096>;
            };
        };
        i2s1 {
            i2s1-2ch-bus {
                rockchip,pins = <0x00000004 0x00000003 0x00000001 0x000000b8 0x00000004 0x00000004 0x00000001 0x000000b8 0x00000004 0x00000005 0x00000001 0x000000b8 0x00000004 0x00000006 0x00000001 0x000000b8 0x00000004 0x00000007 0x00000001 0x000000b8>;
                linux,phandle = <0x00000097>;
                phandle = <0x00000097>;
            };
        };
        sdio0 {
            sdio0-bus1 {
                rockchip,pins = <0x00000002 0x00000014 0x00000001 0x000000bb>;
            };
            sdio0-bus4 {
                rockchip,pins = <0x00000002 0x00000014 0x00000001 0x000000bb 0x00000002 0x00000015 0x00000001 0x000000bb 0x00000002 0x00000016 0x00000001 0x000000bb 0x00000002 0x00000017 0x00000001 0x000000bb>;
                linux,phandle = <0x0000001d>;
                phandle = <0x0000001d>;
            };
            sdio0-cmd {
                rockchip,pins = <0x00000002 0x00000018 0x00000001 0x000000bb>;
                linux,phandle = <0x0000001e>;
                phandle = <0x0000001e>;
            };
            sdio0-clk {
                rockchip,pins = <0x00000002 0x00000019 0x00000001 0x000000bc>;
                linux,phandle = <0x0000001f>;
                phandle = <0x0000001f>;
            };
            sdio0-cd {
                rockchip,pins = <0x00000002 0x0000001a 0x00000001 0x000000b6>;
            };
            sdio0-pwr {
                rockchip,pins = <0x00000002 0x0000001b 0x00000001 0x000000b6>;
            };
            sdio0-bkpwr {
                rockchip,pins = <0x00000002 0x0000001c 0x00000001 0x000000b6>;
            };
            sdio0-wp {
                rockchip,pins = <0x00000000 0x00000003 0x00000001 0x000000b6>;
            };
            sdio0-int {
                rockchip,pins = <0x00000000 0x00000004 0x00000001 0x000000b6>;
            };
        };
        sdmmc {
            sdmmc-bus1 {
                rockchip,pins = <0x00000004 0x00000008 0x00000001 0x000000bd>;
            };
            sdmmc-bus4 {
                rockchip,pins = <0x00000004 0x00000008 0x00000001 0x000000bd 0x00000004 0x00000009 0x00000001 0x000000bd 0x00000004 0x0000000a 0x00000001 0x000000bd 0x00000004 0x0000000b 0x00000001 0x000000bd>;
                linux,phandle = <0x00000024>;
                phandle = <0x00000024>;
            };
            sdmmc-clk {
                rockchip,pins = <0x00000004 0x0000000c 0x00000001 0x000000be>;
                linux,phandle = <0x00000021>;
                phandle = <0x00000021>;
            };
            sdmmc-cmd {
                rockchip,pins = <0x00000004 0x0000000d 0x00000001 0x000000bd>;
                linux,phandle = <0x00000022>;
                phandle = <0x00000022>;
            };
            sdmcc-cd {
                rockchip,pins = <0x00000000 0x00000007 0x00000001 0x000000b6>;
                linux,phandle = <0x00000023>;
                phandle = <0x00000023>;
            };
            sdmmc-wp {
                rockchip,pins = <0x00000000 0x00000008 0x00000001 0x000000b6>;
            };
            sdmmc-en {
                rockchip,pins = <0x00000000 0x00000001 0x00000001 0x000000bf>;
                linux,phandle = <0x000000b2>;
                phandle = <0x000000b2>;
            };
            sdmmc-sleep {
                rockchip,pins = <0x00000000 0x00000001 0x00000001 0x000000b9>;
                linux,phandle = <0x000000b4>;
                phandle = <0x000000b4>;
            };
        };
        spdif {
            spdif-bus {
                rockchip,pins = <0x00000004 0x00000015 0x00000001 0x000000b8>;
            };
            spdif-bus-1 {
                rockchip,pins = <0x00000003 0x00000010 0x00000003 0x000000b8>;
                linux,phandle = <0x00000095>;
                phandle = <0x00000095>;
            };
        };
        spi0 {
            spi0-clk {
                rockchip,pins = <0x00000003 0x00000006 0x00000002 0x000000b6>;
                linux,phandle = <0x00000047>;
                phandle = <0x00000047>;
            };
            spi0-cs0 {
                rockchip,pins = <0x00000003 0x00000007 0x00000002 0x000000b6>;
                linux,phandle = <0x0000004a>;
                phandle = <0x0000004a>;
            };
            spi0-cs1 {
                rockchip,pins = <0x00000003 0x00000008 0x00000002 0x000000b6>;
            };
            spi0-tx {
                rockchip,pins = <0x00000003 0x00000005 0x00000002 0x000000b6>;
                linux,phandle = <0x00000048>;
                phandle = <0x00000048>;
            };
            spi0-rx {
                rockchip,pins = <0x00000003 0x00000004 0x00000002 0x000000b6>;
                linux,phandle = <0x00000049>;
                phandle = <0x00000049>;
            };
        };
        spi1 {
            spi1-clk {
                rockchip,pins = <0x00000001 0x00000009 0x00000002 0x000000b6>;
                linux,phandle = <0x0000004b>;
                phandle = <0x0000004b>;
            };
            spi1-cs0 {
                rockchip,pins = <0x00000001 0x0000000a 0x00000002 0x000000b6>;
                linux,phandle = <0x0000004e>;
                phandle = <0x0000004e>;
            };
            spi1-rx {
                rockchip,pins = <0x00000001 0x00000007 0x00000002 0x000000b6>;
                linux,phandle = <0x0000004d>;
                phandle = <0x0000004d>;
            };
            spi1-tx {
                rockchip,pins = <0x00000001 0x00000008 0x00000002 0x000000b6>;
                linux,phandle = <0x0000004c>;
                phandle = <0x0000004c>;
            };
        };
        spi2 {
            spi2-clk {
                rockchip,pins = <0x00000002 0x0000000b 0x00000001 0x000000b6>;
                linux,phandle = <0x0000004f>;
                phandle = <0x0000004f>;
            };
            spi2-cs0 {
                rockchip,pins = <0x00000002 0x0000000c 0x00000001 0x000000b6>;
                linux,phandle = <0x00000052>;
                phandle = <0x00000052>;
            };
            spi2-rx {
                rockchip,pins = <0x00000002 0x00000009 0x00000001 0x000000b6>;
                linux,phandle = <0x00000051>;
                phandle = <0x00000051>;
            };
            spi2-tx {
                rockchip,pins = <0x00000002 0x0000000a 0x00000001 0x000000b6>;
                linux,phandle = <0x00000050>;
                phandle = <0x00000050>;
            };
        };
        spi3 {
            spi3-clk {
                rockchip,pins = <0x00000001 0x00000011 0x00000001 0x000000b6>;
                linux,phandle = <0x00000078>;
                phandle = <0x00000078>;
            };
            spi3-cs0 {
                rockchip,pins = <0x00000001 0x00000012 0x00000001 0x000000b6>;
                linux,phandle = <0x0000007b>;
                phandle = <0x0000007b>;
            };
            spi3-rx {
                rockchip,pins = <0x00000001 0x0000000f 0x00000001 0x000000b6>;
                linux,phandle = <0x0000007a>;
                phandle = <0x0000007a>;
            };
            spi3-tx {
                rockchip,pins = <0x00000001 0x00000010 0x00000001 0x000000b6>;
                linux,phandle = <0x00000079>;
                phandle = <0x00000079>;
            };
        };
        spi4 {
            spi4-clk {
                rockchip,pins = <0x00000003 0x00000002 0x00000002 0x000000b6>;
                linux,phandle = <0x00000053>;
                phandle = <0x00000053>;
            };
            spi4-cs0 {
                rockchip,pins = <0x00000003 0x00000003 0x00000002 0x000000b6>;
                linux,phandle = <0x00000056>;
                phandle = <0x00000056>;
            };
            spi4-rx {
                rockchip,pins = <0x00000003 0x00000000 0x00000002 0x000000b6>;
                linux,phandle = <0x00000055>;
                phandle = <0x00000055>;
            };
            spi4-tx {
                rockchip,pins = <0x00000003 0x00000001 0x00000002 0x000000b6>;
                linux,phandle = <0x00000054>;
                phandle = <0x00000054>;
            };
        };
        spi5 {
            spi5-clk {
                rockchip,pins = <0x00000002 0x00000016 0x00000002 0x000000b6>;
                linux,phandle = <0x00000057>;
                phandle = <0x00000057>;
            };
            spi5-cs0 {
                rockchip,pins = <0x00000002 0x00000017 0x00000002 0x000000b6>;
                linux,phandle = <0x0000005a>;
                phandle = <0x0000005a>;
            };
            spi5-rx {
                rockchip,pins = <0x00000002 0x00000014 0x00000002 0x000000b6>;
                linux,phandle = <0x00000059>;
                phandle = <0x00000059>;
            };
            spi5-tx {
                rockchip,pins = <0x00000002 0x00000015 0x00000002 0x000000b6>;
                linux,phandle = <0x00000058>;
                phandle = <0x00000058>;
            };
        };
        tsadc {
            otp-gpio {
                rockchip,pins = <0x00000001 0x00000006 0x00000000 0x000000b8>;
                linux,phandle = <0x0000005e>;
                phandle = <0x0000005e>;
            };
            otp-out {
                rockchip,pins = <0x00000001 0x00000006 0x00000001 0x000000b8>;
                linux,phandle = <0x0000005f>;
                phandle = <0x0000005f>;
            };
        };
        uart0 {
            uart0-xfer {
                rockchip,pins = <0x00000002 0x00000010 0x00000001 0x000000b6 0x00000002 0x00000011 0x00000001 0x000000b8>;
                linux,phandle = <0x00000040>;
                phandle = <0x00000040>;
            };
            uart0-cts {
                rockchip,pins = <0x00000002 0x00000012 0x00000001 0x000000b8>;
                linux,phandle = <0x00000041>;
                phandle = <0x00000041>;
            };
            uart0-rts {
                rockchip,pins = <0x00000002 0x00000013 0x00000001 0x000000b8>;
                linux,phandle = <0x000000d5>;
                phandle = <0x000000d5>;
            };
        };
        uart1 {
            uart1-xfer {
                rockchip,pins = <0x00000003 0x0000000c 0x00000002 0x000000b6 0x00000003 0x0000000d 0x00000002 0x000000b8>;
                linux,phandle = <0x00000042>;
                phandle = <0x00000042>;
            };
        };
        uart2a {
            uart2a-xfer {
                rockchip,pins = <0x00000004 0x00000008 0x00000002 0x000000b6 0x00000004 0x00000009 0x00000002 0x000000b8>;
            };
        };
        uart2b {
            uart2b-xfer {
                rockchip,pins = <0x00000004 0x00000010 0x00000002 0x000000b6 0x00000004 0x00000011 0x00000002 0x000000b8>;
            };
        };
        uart2c {
            uart2c-xfer {
                rockchip,pins = <0x00000004 0x00000013 0x00000001 0x000000b6 0x00000004 0x00000014 0x00000001 0x000000b8>;
                linux,phandle = <0x00000043>;
                phandle = <0x00000043>;
            };
        };
        uart3 {
            uart3-xfer {
                rockchip,pins = <0x00000003 0x0000000e 0x00000002 0x000000b6 0x00000003 0x0000000f 0x00000002 0x000000b8>;
                linux,phandle = <0x00000044>;
                phandle = <0x00000044>;
            };
            uart3-cts {
                rockchip,pins = <0x00000003 0x00000012 0x00000002 0x000000b8>;
                linux,phandle = <0x00000045>;
                phandle = <0x00000045>;
            };
            uart3-rts {
                rockchip,pins = <0x00000003 0x00000013 0x00000002 0x000000b8>;
                linux,phandle = <0x00000046>;
                phandle = <0x00000046>;
            };
        };
        uart4 {
            uart4-xfer {
                rockchip,pins = <0x00000001 0x00000007 0x00000001 0x000000b6 0x00000001 0x00000008 0x00000001 0x000000b8>;
                linux,phandle = <0x0000007c>;
                phandle = <0x0000007c>;
            };
        };
        uarthdcp {
            uarthdcp-xfer {
                rockchip,pins = <0x00000004 0x00000015 0x00000002 0x000000b6 0x00000004 0x00000016 0x00000002 0x000000b8>;
            };
        };
        pwm0 {
            pwm0-pin {
                rockchip,pins = <0x00000004 0x00000012 0x00000001 0x000000b8>;
                linux,phandle = <0x00000085>;
                phandle = <0x00000085>;
            };
            vop0-pwm-pin {
                rockchip,pins = <0x00000004 0x00000012 0x00000002 0x000000b8>;
                linux,phandle = <0x000000a5>;
                phandle = <0x000000a5>;
            };
        };
        pwm1 {
            pwm1-pin {
                rockchip,pins = <0x00000004 0x00000016 0x00000001 0x000000b8>;
                linux,phandle = <0x00000086>;
                phandle = <0x00000086>;
            };
            vop1-pwm-pin {
                rockchip,pins = <0x00000004 0x00000012 0x00000003 0x000000b8>;
                linux,phandle = <0x0000009f>;
                phandle = <0x0000009f>;
            };
        };
        pwm2 {
            pwm2-pin {
                rockchip,pins = <0x00000001 0x00000013 0x00000001 0x000000b8>;
                linux,phandle = <0x00000087>;
                phandle = <0x00000087>;
            };
        };
        pwm3a {
            pwm3a-pin {
                rockchip,pins = <0x00000000 0x00000006 0x00000001 0x000000b8>;
                linux,phandle = <0x00000088>;
                phandle = <0x00000088>;
            };
        };
        pwm3b {
            pwm3b-pin {
                rockchip,pins = <0x00000001 0x0000000e 0x00000001 0x000000b8>;
            };
        };
        edp {
            edp-hpd {
                rockchip,pins = <0x00000004 0x00000017 0x00000002 0x000000b8>;
                linux,phandle = <0x000000ab>;
                phandle = <0x000000ab>;
            };
        };
        hdmi {
            hdmi-i2c-xfer {
                rockchip,pins = <0x00000004 0x00000011 0x00000003 0x000000b8 0x00000004 0x00000010 0x00000003 0x000000b8>;
                linux,phandle = <0x000000a6>;
                phandle = <0x000000a6>;
            };
            hdmi-cec {
                rockchip,pins = <0x00000004 0x00000017 0x00000001 0x000000b8>;
            };
            hdmi-en {
                rockchip,pins = <0x00000001 0x0000000d 0x00000000 0x000000bf 0x00000004 0x0000001c 0x00000000 0x000000bf>;
                linux,phandle = <0x000000b1>;
                phandle = <0x000000b1>;
            };
            hdmi-sleep {
                rockchip,pins = <0x00000004 0x0000001c 0x00000000 0x000000b9>;
            };
        };
        pcie {
            pci-clkreqn {
                rockchip,pins = <0x00000002 0x0000001a 0x00000002 0x000000b8>;
                linux,phandle = <0x00000084>;
                phandle = <0x00000084>;
            };
            pci-clkreqnb {
                rockchip,pins = <0x00000004 0x00000018 0x00000001 0x000000b8>;
            };
            pci-clkreqn-cpm {
                rockchip,pins = <0x00000002 0x0000001a 0x00000000 0x000000b8>;
            };
            pci-clkreqnb-cpm {
                rockchip,pins = <0x00000004 0x00000018 0x00000000 0x000000b8>;
            };
        };
        isp {
            cif-clkout {
                rockchip,pins = <0x00000002 0x0000000b 0x00000003 0x000000b8>;
                linux,phandle = <0x000000c4>;
                phandle = <0x000000c4>;
            };
            isp-dvp-d0d7 {
                rockchip,pins = <0x00000002 0x00000000 0x00000003 0x000000b8 0x00000002 0x00000001 0x00000003 0x000000b8 0x00000002 0x00000002 0x00000003 0x000000b8 0x00000002 0x00000003 0x00000003 0x000000b8 0x00000002 0x00000004 0x00000003 0x000000b8 0x00000002 0x00000005 0x00000003 0x000000b8 0x00000002 0x00000006 0x00000003 0x000000b8 0x00000002 0x00000007 0x00000003 0x000000b8 0x00000002 0x00000008 0x00000003 0x000000b8 0x00000002 0x00000009 0x00000003 0x000000b8 0x00000002 0x0000000a 0x00000003 0x000000b8>;
                linux,phandle = <0x000000c5>;
                phandle = <0x000000c5>;
            };
            isp-shutter {
                rockchip,pins = <0x00000001 0x00000001 0x00000001 0x000000b8 0x00000001 0x00000000 0x00000001 0x000000b8>;
            };
            isp-flash-trigger {
                rockchip,pins = <0x00000001 0x00000003 0x00000001 0x000000b8>;
                linux,phandle = <0x000000c8>;
                phandle = <0x000000c8>;
            };
            isp-prelight {
                rockchip,pins = <0x00000001 0x00000004 0x00000001 0x000000b8>;
                linux,phandle = <0x000000c6>;
                phandle = <0x000000c6>;
            };
            isp_flash_trigger_as_gpio {
                rockchip,pins = <0x00000001 0x00000003 0x00000000 0x000000b8>;
                linux,phandle = <0x000000c7>;
                phandle = <0x000000c7>;
            };
        };
        sdio-pwrseq {
            wifi-enable-h {
                rockchip,pins = <0x00000001 0x00000004 0x00000000 0x000000b8>;
                linux,phandle = <0x000000d4>;
                phandle = <0x000000d4>;
            };
        };
        wireless-bluetooth {
            uart0-gpios {
                rockchip,pins = <0x00000002 0x00000013 0x00000000 0x000000b8>;
                linux,phandle = <0x000000d6>;
                phandle = <0x000000d6>;
            };
        };
        usb2 {
            host-vbus-drv {
                rockchip,pins = <0x00000001 0x00000003 0x00000000 0x000000b8>;
                linux,phandle = <0x000000cf>;
                phandle = <0x000000cf>;
            };
        };
        eth_phy {
            eth-phy-pwr {
                rockchip,pins = <0x00000001 0x0000000d 0x00000000 0x000000b8>;
                linux,phandle = <0x000000ce>;
                phandle = <0x000000ce>;
            };
        };
        pmic {
            pmic-int-l {
                rockchip,pins = <0x00000001 0x00000015 0x00000000 0x000000b6>;
                linux,phandle = <0x00000037>;
                phandle = <0x00000037>;
            };
            vsel1-gpio {
                rockchip,pins = <0x00000001 0x00000011 0x00000000 0x000000c0>;
                linux,phandle = <0x00000034>;
                phandle = <0x00000034>;
            };
            vsel2-gpio {
                rockchip,pins = <0x00000001 0x0000000e 0x00000000 0x000000c0>;
                linux,phandle = <0x00000036>;
                phandle = <0x00000036>;
            };
        };
        am40_gpio {
            pwr-en {
                rockchip,pins = <0x00000000 0x0000000a 0x00000000 0x000000bf 0x00000000 0x0000000b 0x00000000 0x000000bf 0x00000001 0x00000004 0x00000000 0x000000bf>;
                linux,phandle = <0x000000b3>;
                phandle = <0x000000b3>;
            };
            pwr-sleep {
                rockchip,pins = <0x00000002 0x0000001c 0x00000000 0x000000b9 0x00000004 0x0000001d 0x00000000 0x000000b9>;
                linux,phandle = <0x000000b5>;
                phandle = <0x000000b5>;
            };
        };
        pt7c_irq {
            pt7c4563-irq {
                rockchip,pins = <0x00000000 0x00000006 0x00000000 0x000000b6>;
                linux,phandle = <0x0000007f>;
                phandle = <0x0000007f>;
            };
        };
    };
    rockchip-suspend {
        compatible = "rockchip,pm-rk3399";
        status = "okay";
        rockchip,sleep-debug-en = <0x00000001>;
        rockchip,virtual-poweroff = <0x00000000>;
        rockchip,sleep-mode-config = <0x000000ce>;
        rockchip,wakeup-config = <0x00004084>;
        rockchip,pwm-regulator-config = <0x00000004>;
        rockchip,power-ctrl = <0x0000001a 0x00000011 0x00000000 0x0000001a 0x0000000e 0x00000000>;
    };
    chosen {
        linux,initrd-end = <0x00000000 0x05d9daf8>;
        linux,initrd-start = <0x00000000 0x05bf0000>;
        bootargs = "earlycon=uart8250,mmio32,0xff1a0000 swiotlb=1 androidboot.baseband=N/A androidboot.selinux=permissive androidboot.hardware=rk30board androidboot.console=ttyFIQ0 init=/init mtdparts=rk29xxnand:0x00002000@0x00002000(uboot),0x00002000@0x00004000(trust),0x00002000@0x00006000(misc),0x00008000@0x00008000(resource),0x0000C000@0x00010000(kernel),0x00010000@0x0001C000(boot),0x00020000@0x0002C000(recovery),0x00002000@0x0004C000(assetdata),0x00002000@0x0004E000(wolodata),0x00034000@0x00050000(backup),0x00200000@0x00084000(cache),0x00600000@0x00284000(system),0x00008000@0x00884000(metadata),0x00002000@0x0088C000(baseparamer),-@0x0088E000(userdata) storagemedia=emmc uboot_logo=0x02000000@0xf5c00000 loader.timestamp=2018-03-26_13:55:07 hdmi.vic=-1 SecureBootCheckOk=0 androidboot.serialno=VACW02184400AY WOLO_MAC=F4939FF10B2A";
    };
    cpuinfo {
        compatible = "rockchip,cpuinfo";
        nvmem-cells = <0x000000c1>;
        nvmem-cell-names = "id";
    };
    ramoops_mem {
        reg = <0x00000000 0x00110000 0x00000000 0x000f0000>;
        reg-names = "ramoops_mem";
        linux,phandle = <0x000000c2>;
        phandle = <0x000000c2>;
    };
    ramoops {
        compatible = "ramoops";
        record-size = <0x00000000 0x00020000>;
        console-size = <0x00000000 0x00080000>;
        ftrace-size = <0x00000000 0x00000000>;
        pmsg-size = <0x00000000 0x00050000>;
        memory-region = <0x000000c2>;
    };
    fiq-debugger {
        compatible = "rockchip,fiq-debugger";
        rockchip,serial-id = <0x00000002>;
        rockchip,signal-irq = <0x000000b6>;
        rockchip,wake-irq = <0x00000000>;
        rockchip,irq-mode-enable = <0x00000001>;
        rockchip,baudrate = <0x0016e360>;
        pinctrl-names = "default";
        pinctrl-0 = <0x00000043>;
    };
    reserved-memory {
        #address-cells = <0x00000002>;
        #size-cells = <0x00000002>;
        ranges;
        drm-logo@00000000 {
            compatible = "rockchip,drm-logo";
            reg = <0x00000000 0xf5c00000 0x00000000 0x005eec36>;
            linux,phandle = <0x000000b0>;
            phandle = <0x000000b0>;
        };
    };
    rockchip-key {
        compatible = "rockchip,key";
        status = "okay";
        io-channels = <0x000000c3 0x00000001>;
        vol-up-key {
            linux,code = <0x00000073>;
            label = "volume up";
            rockchip,adc_value = <0x00000001>;
        };
        vol-down-key {
            linux,code = <0x00000072>;
            label = "volume down";
            rockchip,adc_value = <0x000000aa>;
        };
        power-key {
            gpios = <0x0000007e 0x00000005 0x00000001>;
            linux,code = <0x00000074>;
            label = "power";
            gpio-key,wakeup;
        };
        menu-key {
            linux,code = <0x0000003b>;
            label = "menu";
            rockchip,adc_value = <0x000002ea>;
        };
        home-key {
            linux,code = <0x00000066>;
            label = "home";
            rockchip,adc_value = <0x00000163>;
        };
        back-key {
            linux,code = <0x0000009e>;
            label = "back";
            rockchip,adc_value = <0x00000230>;
        };
        camera-key {
            linux,code = <0x000000d4>;
            label = "camera";
            rockchip,adc_value = <0x000001c2>;
        };
    };
    isp@ff910000 {
        compatible = "rockchip,rk3399-isp", "rockchip,isp";
        reg = <0x00000000 0xff910000 0x00000000 0x00004000>;
        interrupts = <0x00000000 0x0000002b 0x00000004 0x00000000>;
        clocks = <0x00000008 0x00000089 0x00000008 0x00000089 0x00000008 0x000000a4 0x00000008 0x00000077 0x00000008 0x000000e7 0x00000008 0x000000e9 0x00000008 0x000001e1 0x00000008 0x000001e3 0x00000008 0x0000006e 0x00000008 0x000000a5>;
        clock-names = "clk_cif_out", "clk_cif_pll", "pclk_dphytxrx", "pclk_dphy_ref", "aclk_isp0_noc", "aclk_isp0_wrapper", "hclk_isp0_noc", "hclk_isp0_wrapper", "clk_isp0", "pclk_dphyrx";
        pinctrl-names = "cif_clkout", "isp_dvp8bit0", "isp_mipi_fl", "isp_mipi_fl_prefl", "isp_flash_as_gpio", "isp_flash_as_trigger_out";
        pinctrl-0 = <0x000000c4>;
        pinctrl-1 = <0x000000c5>;
        pinctrl-2 = <0x000000c4>;
        pinctrl-3 = <0x000000c6>;
        pinctrl-4 = <0x000000c7>;
        pinctrl-5 = <0x000000c8>;
        rockchip,isp,mipiphy = <0x00000002>;
        rockchip,isp,cifphy = <0x00000001>;
        rockchip,isp,dsiphy,reg = <0xff968000 0x00008000>;
        rockchip,grf = <0x00000015>;
        rockchip,cru = <0x00000008>;
        rockchip,gpios = <0x0000001a 0x00000003 0x00000000>;
        rockchip,isp,iommu-enable = <0x00000001>;
        power-domains = <0x0000001b 0x00000013>;
        iommus = <0x000000c9>;
        status = "disabled";
    };
    isp@ff920000 {
        compatible = "rockchip,rk3399-isp", "rockchip,isp";
        reg = <0x00000000 0xff920000 0x00000000 0x00004000>;
        interrupts = <0x00000000 0x0000002c 0x00000004 0x00000000>;
        clocks = <0x00000008 0x000000e8 0x00000008 0x000000ea 0x00000008 0x000001e2 0x00000008 0x000001e4 0x00000008 0x0000006f 0x00000008 0x00000089 0x00000008 0x00000089 0x00000008 0x000000a4 0x00000008 0x00000077 0x00000008 0x0000017b 0x00000008 0x000000a5 0x00000008 0x00000171 0x00000008 0x00000078>;
        clock-names = "aclk_isp1_noc", "aclk_isp1_wrapper", "hclk_isp1_noc", "hclk_isp1_wrapper", "clk_isp1", "clk_cif_out", "clk_cif_pll", "pclk_dphytxrx", "pclk_dphy_ref", "pclk_isp1", "pclk_dphyrx", "pclk_mipi_dsi", "mipi_dphy_cfg";
        pinctrl-names = "cif_clkout", "isp_dvp8bit0", "isp_mipi_fl", "isp_mipi_fl_prefl", "isp_flash_as_gpio", "isp_flash_as_trigger_out";
        pinctrl-0 = <0x000000c4>;
        pinctrl-1 = <0x000000c5>;
        pinctrl-2 = <0x000000c4>;
        pinctrl-3 = <0x000000c6>;
        pinctrl-4 = <0x000000c7>;
        pinctrl-5 = <0x000000c8>;
        rockchip,isp,mipiphy = <0x00000002>;
        rockchip,isp,cifphy = <0x00000001>;
        rockchip,isp,dsiphy,reg = <0xff968000 0x00008000>;
        rockchip,grf = <0x00000015>;
        rockchip,cru = <0x00000008>;
        rockchip,gpios = <0x0000001a 0x00000003 0x00000000>;
        rockchip,isp,iommu-enable = <0x00000001>;
        power-domains = <0x0000001b 0x00000014>;
        iommus = <0x000000ca>;
        status = "disabled";
    };
    uboot-charge {
        compatible = "rockchip,uboot-charge";
        rockchip,uboot-charge-on = <0x00000001>;
        rockchip,android-charge-on = <0x00000000>;
    };
    hdmi-dp-sound {
        status = "okay";
        compatible = "rockchip,rk3399-hdmi-dp";
        rockchip,cpu = <0x000000cb>;
        rockchip,codec = <0x000000cc 0x000000cd>;
    };
    energy-costs {
        rk3399-core-cost0 {
            busy-cost-data = <0x0000006c 0x0000002e 0x0000009f 0x00000043 0x000000d8 0x0000005a 0x0000010b 0x00000078 0x0000013e 0x00000099 0x00000177 0x000000c6 0x00000191 0x000000de>;
            idle-cost-data = <0x00000006 0x00000006 0x00000000 0x00000000>;
            linux,phandle = <0x0000000c>;
            phandle = <0x0000000c>;
        };
        rk3399-core-cost1 {
            busy-cost-data = <0x000000d2 0x00000081 0x00000134 0x000000b8 0x000001a3 0x000000f6 0x00000206 0x0000014f 0x00000269 0x000001ac 0x000002d8 0x0000023d 0x0000033b 0x000002d4 0x0000039d 0x00000384 0x00000400 0x00000454>;
            idle-cost-data = <0x0000000f 0x0000000f 0x00000000 0x00000000>;
            linux,phandle = <0x00000010>;
            phandle = <0x00000010>;
        };
        rk3399-cluster-cost0 {
            busy-cost-data = <0x0000006c 0x0000002e 0x0000009f 0x00000043 0x000000d8 0x0000005a 0x0000010b 0x00000078 0x0000013e 0x00000099 0x00000177 0x000000c6 0x00000191 0x000000de>;
            idle-cost-data = <0x00000038 0x00000038 0x00000038 0x00000038>;
            linux,phandle = <0x0000000d>;
            phandle = <0x0000000d>;
        };
        rk3399-cluster-cost1 {
            busy-cost-data = <0x000000d2 0x00000081 0x00000134 0x000000b8 0x000001a3 0x000000f6 0x00000206 0x0000014f 0x00000269 0x000001ac 0x000002d8 0x0000023d 0x0000033b 0x000002d4 0x0000039d 0x00000384 0x00000400 0x00000454>;
            idle-cost-data = <0x00000041 0x00000041 0x00000041 0x00000041>;
            linux,phandle = <0x00000011>;
            phandle = <0x00000011>;
        };
    };
    opp-table0 {
        compatible = "operating-points-v2";
        opp-shared;
        linux,phandle = <0x0000000b>;
        phandle = <0x0000000b>;
        opp-408000000 {
            opp-hz = <0x00000000 0x18519600>;
            opp-microvolt = <0x000c3500>;
            clock-latency-ns = <0x00009c40>;
        };
        opp-600000000 {
            opp-hz = <0x00000000 0x23c34600>;
            opp-microvolt = <0x000c3500>;
            clock-latency-ns = <0x00009c40>;
        };
        opp-816000000 {
            opp-hz = <0x00000000 0x30a32c00>;
            opp-microvolt = <0x000cf850>;
            clock-latency-ns = <0x00009c40>;
            opp-suspend;
        };
        opp-1008000000 {
            opp-hz = <0x00000000 0x3c14dc00>;
            opp-microvolt = <0x000e1d48>;
            clock-latency-ns = <0x00009c40>;
        };
        opp-1200000000 {
            opp-hz = <0x00000000 0x47868c00>;
            opp-microvolt = <0x000f4240>;
            clock-latency-ns = <0x00009c40>;
        };
        opp-1416000000 {
            opp-hz = <0x00000000 0x54667200>;
            opp-microvolt = <0x00112a88>;
            clock-latency-ns = <0x00009c40>;
        };
    };
    opp-table1 {
        compatible = "operating-points-v2";
        opp-shared;
        linux,phandle = <0x0000000f>;
        phandle = <0x0000000f>;
        opp-408000000 {
            opp-hz = <0x00000000 0x18519600>;
            opp-microvolt = <0x000c3500>;
            clock-latency-ns = <0x00009c40>;
        };
        opp-600000000 {
            opp-hz = <0x00000000 0x23c34600>;
            opp-microvolt = <0x000c3500>;
            clock-latency-ns = <0x00009c40>;
        };
        opp-816000000 {
            opp-hz = <0x00000000 0x30a32c00>;
            opp-microvolt = <0x000c96a8>;
            clock-latency-ns = <0x00009c40>;
            opp-suspend;
        };
        opp-1008000000 {
            opp-hz = <0x00000000 0x3c14dc00>;
            opp-microvolt = <0x000d59f8>;
            clock-latency-ns = <0x00009c40>;
        };
        opp-1200000000 {
            opp-hz = <0x00000000 0x47868c00>;
            opp-microvolt = <0x000e7ef0>;
            clock-latency-ns = <0x00009c40>;
        };
        opp-1416000000 {
            opp-hz = <0x00000000 0x54667200>;
            opp-microvolt = <0x000fa3e8>;
            clock-latency-ns = <0x00009c40>;
        };
        opp-1608000000 {
            opp-hz = <0x00000000 0x5fd82200>;
            opp-microvolt = <0x0010c8e0>;
            clock-latency-ns = <0x00009c40>;
        };
        opp-1800000000 {
            opp-hz = <0x00000000 0x6b49d200>;
            opp-microvolt = <0x00124f80>;
            clock-latency-ns = <0x00009c40>;
        };
    };
    opp-table2 {
        compatible = "operating-points-v2";
        linux,phandle = <0x00000098>;
        phandle = <0x00000098>;
        opp-200000000 {
            opp-hz = <0x00000000 0x0bebc200>;
            opp-microvolt = <0x000c3500>;
        };
        opp-297000000 {
            opp-hz = <0x00000000 0x11b3dc40>;
            opp-microvolt = <0x000c3500>;
        };
        opp-400000000 {
            opp-hz = <0x00000000 0x17d78400>;
            opp-microvolt = <0x000c96a8>;
        };
        opp-500000000 {
            opp-hz = <0x00000000 0x1dcd6500>;
            opp-microvolt = <0x000d59f8>;
        };
        opp-594000000 {
            opp-hz = <0x00000000 0x2367b880>;
            opp-microvolt = <0x000e1d48>;
        };
        opp-800000000 {
            opp-hz = <0x00000000 0x2faf0800>;
            opp-microvolt = <0x0010c8e0>;
        };
    };
    opp-table3 {
        compatible = "operating-points-v2";
        linux,phandle = <0x0000008c>;
        phandle = <0x0000008c>;
        opp-200000000 {
            opp-hz = <0x00000000 0x0bebc200>;
            opp-microvolt = <0x000c96a8>;
        };
        opp-297000000 {
            opp-hz = <0x00000000 0x11b3dc40>;
            opp-microvolt = <0x000cf850>;
        };
        opp-400000000 {
            opp-hz = <0x00000000 0x17d78400>;
            opp-microvolt = <0x000cf850>;
        };
        opp-594000000 {
            opp-hz = <0x00000000 0x2367b880>;
            opp-microvolt = <0x000dbba0>;
        };
        opp-800000000 {
            opp-hz = <0x00000000 0x2faf0800>;
            opp-microvolt = <0x000dbba0>;
        };
    };
    vcc1v8-s0 {
        compatible = "regulator-fixed";
        regulator-name = "vcc1v8_s0";
        regulator-min-microvolt = <0x001b7740>;
        regulator-max-microvolt = <0x001b7740>;
        regulator-always-on;
        linux,phandle = <0x00000090>;
        phandle = <0x00000090>;
    };
    vcc-sys {
        compatible = "regulator-fixed";
        regulator-name = "vcc_sys";
        regulator-min-microvolt = <0x004c4b40>;
        regulator-max-microvolt = <0x004c4b40>;
        regulator-always-on;
        linux,phandle = <0x00000035>;
        phandle = <0x00000035>;
    };
    vcc-phy-regulator {
        compatible = "regulator-fixed";
        enable-active-high;
        regulator-name = "vcc_phy";
        gpio = <0x0000001a 0x0000000d 0x00000000>;
        pinctrl-names = "default";
        pinctrl-0 = <0x000000ce>;
        regulator-always-on;
        regulator-boot-on;
        linux,phandle = <0x00000016>;
        phandle = <0x00000016>;
    };
    vcc3v3-sys {
        compatible = "regulator-fixed";
        regulator-name = "vcc3v3_sys";
        regulator-min-microvolt = <0x00325aa0>;
        regulator-max-microvolt = <0x00325aa0>;
        regulator-always-on;
        vin-supply = <0x00000035>;
        linux,phandle = <0x00000038>;
        phandle = <0x00000038>;
    };
    vcc5v0-host-regulator {
        compatible = "regulator-fixed";
        enable-active-high;
        gpio = <0x0000001a 0x00000003 0x00000000>;
        pinctrl-names = "default";
        pinctrl-0 = <0x000000cf>;
        regulator-name = "vcc5v0_host";
        regulator-always-on;
        linux,phandle = <0x00000093>;
        phandle = <0x00000093>;
    };
    vdd-log {
        compatible = "pwm-regulator";
        pwms = <0x000000d0 0x00000000 0x000061a8 0x00000001>;
        regulator-name = "vdd_log";
        regulator-min-microvolt = <0x000c3500>;
        regulator-max-microvolt = <0x00155cc0>;
        regulator-always-on;
        regulator-boot-on;
        rockchip,pwm_id = <0x00000002>;
        rockchip,pwm_voltage = <0x000dbba0>;
        vin-supply = <0x00000035>;
    };
    external-gmac-clock {
        compatible = "fixed-clock";
        clock-frequency = <0x07735940>;
        clock-output-names = "clkin_gmac";
        #clock-cells = <0x00000000>;
        linux,phandle = <0x00000018>;
        phandle = <0x00000018>;
    };
    spdif-sound {
        status = "okay";
        compatible = "simple-audio-card";
        simple-audio-card,name = "ROCKCHIP,SPDIF";
        simple-audio-card,cpu {
            sound-dai = <0x000000d1>;
        };
        simple-audio-card,codec {
            sound-dai = <0x000000d2>;
        };
    };
    spdif-out {
        status = "okay";
        compatible = "linux,spdif-dit";
        #sound-dai-cells = <0x00000000>;
        linux,phandle = <0x000000d2>;
        phandle = <0x000000d2>;
    };
    sdio-pwrseq {
        compatible = "mmc-pwrseq-simple";
        clocks = <0x000000d3 0x00000001>;
        clock-names = "ext_clock";
        pinctrl-names = "default";
        pinctrl-0 = <0x000000d4>;
        reset-gpios = <0x0000007e 0x0000000a 0x00000001>;
        linux,phandle = <0x0000001c>;
        phandle = <0x0000001c>;
    };
    wireless-wlan {
        compatible = "wlan-platdata";
        rockchip,grf = <0x00000015>;
        wifi_chip_type = "ap6354";
        sdio_vref = <0x00000708>;
        WIFI,host_wake_irq = <0x0000007e 0x00000003 0x00000000>;
        status = "disabled";
    };
    wireless-bluetooth {
        compatible = "bluetooth-platdata";
        clocks = <0x000000d3 0x00000001>;
        clock-names = "ext_clock";
        pinctrl-names = "default", "rts_gpio";
        pinctrl-0 = <0x000000d5>;
        pinctrl-1 = <0x000000d6>;
        status = "okay";
    };
    test-power {
        status = "okay";
    };
    power-led {
        compatible = "power,am40-led";
        power-led-gpios = <0x000000d7 0x00000012 0x00000001>;
    };
    virtual-pd0 {
        compatible = "linux,extcon-pd-virtual";
        dp-det-gpios = <0x000000d7 0x00000019 0x00000001>;
        hdmi-5v-gpios = <0x000000d7 0x0000001c 0x00000001>;
        vpd,init-flip = <0x00000000>;
        vpd,init-ss = <0x00000000>;
        vpd,init-mode = <0x00000003>;
        linux,phandle = <0x0000002f>;
        phandle = <0x0000002f>;
    };
};
